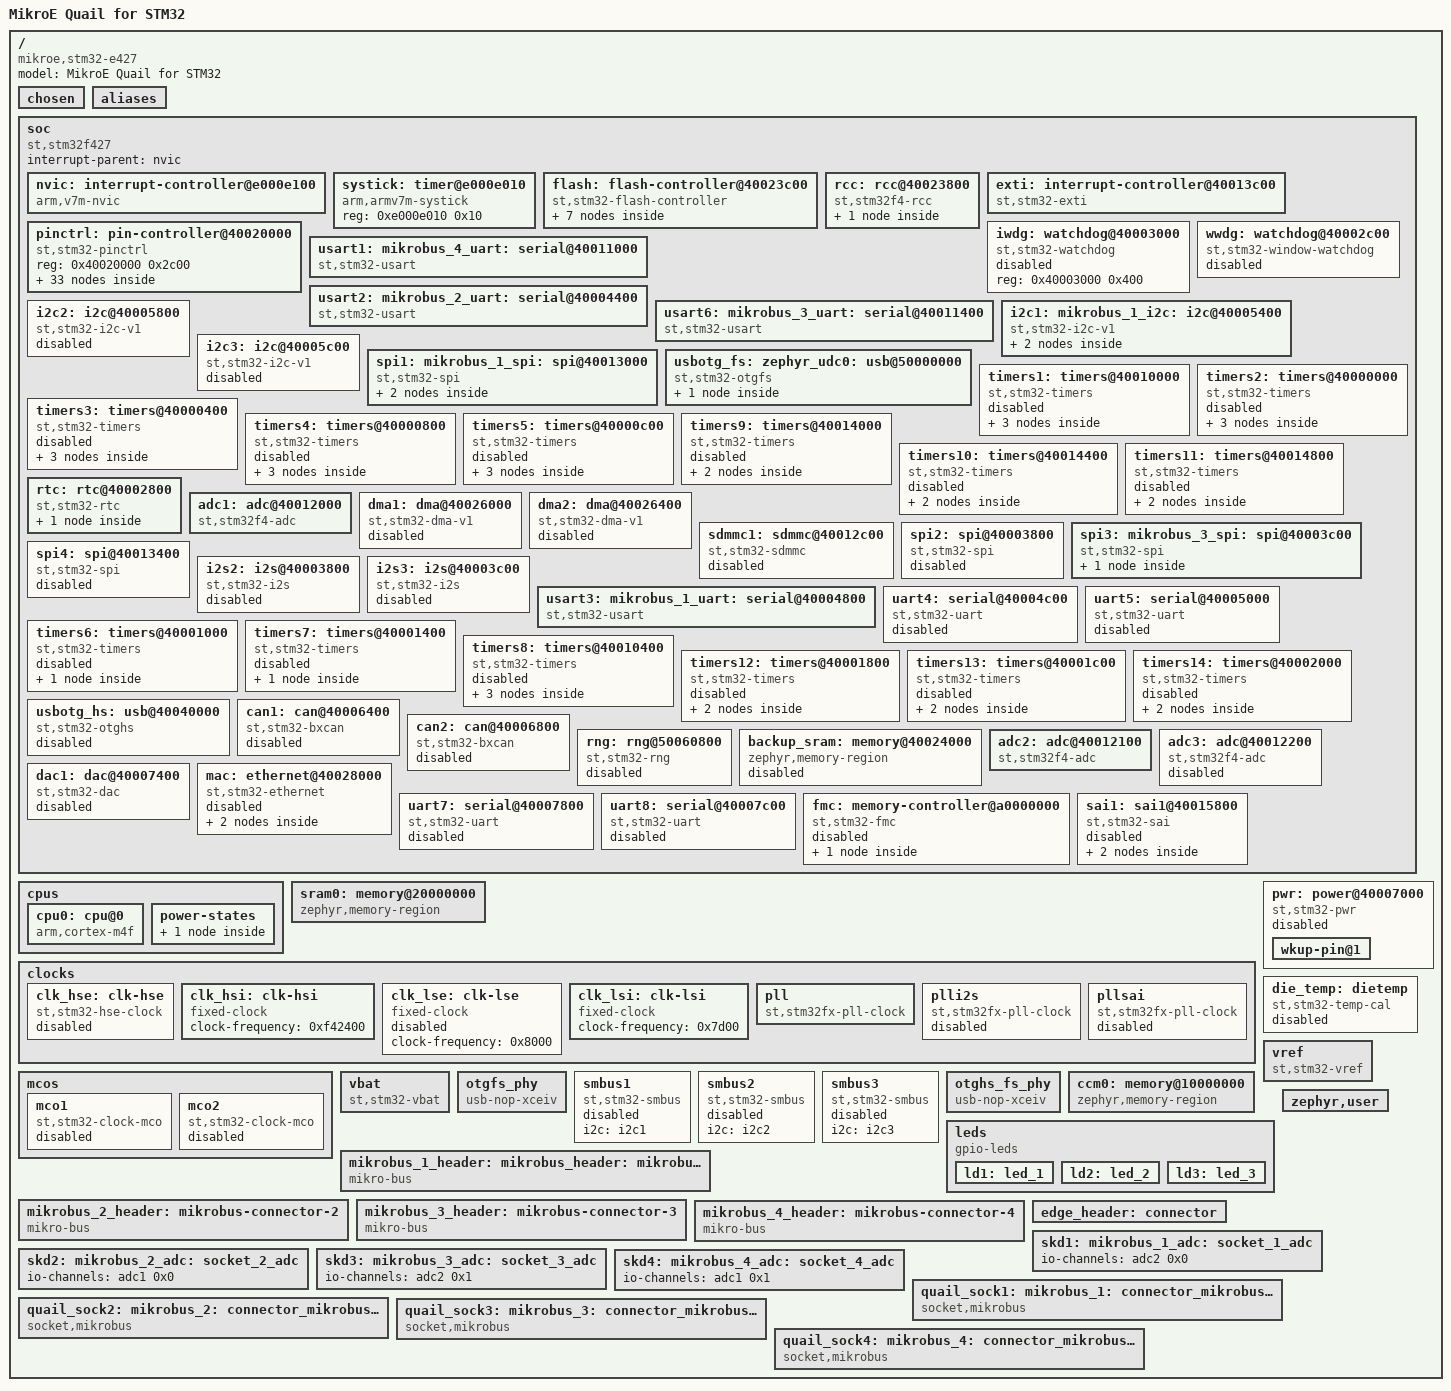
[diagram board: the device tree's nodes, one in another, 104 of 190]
/dts-v1/;

/* node '/' defined in zephyr/dts/common/skeleton.dtsi:9 */
/ {
	#address-cells = < 0x1 >;         /* in zephyr/dts/common/skeleton.dtsi:10 */
	#size-cells = < 0x1 >;            /* in zephyr/dts/common/skeleton.dtsi:11 */
	model = "MikroE Quail for STM32"; /* in zephyr/boards/mikroe/quail/mikroe_quail.dts:13 */
	compatible = "mikroe,stm32-e427",
	             "st,stm32f427";      /* in zephyr/boards/mikroe/quail/mikroe_quail.dts:14 */

	/* node '/chosen' defined in zephyr/dts/common/skeleton.dtsi:13 */
	chosen {
		zephyr,system-timer-companion = &rtc;     /* in zephyr/dts/arm/st/f4/stm32f4.dtsi:27 */
		zephyr,entropy = &rng;                    /* in zephyr/dts/arm/st/f4/stm32f405.dtsi:13 */
		zephyr,sram = &sram0;                     /* in zephyr/boards/mikroe/quail/mikroe_quail.dts:17 */
		zephyr,flash = &flash0;                   /* in zephyr/boards/mikroe/quail/mikroe_quail.dts:18 */
		zephyr,flash-controller = &flash1;        /* in zephyr/boards/mikroe/quail/mikroe_quail.dts:19 */
		zephyr,dtcm = &ccm0;                      /* in zephyr/boards/mikroe/quail/mikroe_quail.dts:20 */
		zephyr,console = &board_cdc_acm_uart;     /* in zephyr/boards/common/usb/cdc_acm_serial.dtsi:9 */
		zephyr,shell-uart = &board_cdc_acm_uart;  /* in zephyr/boards/common/usb/cdc_acm_serial.dtsi:10 */
		zephyr,uart-mcumgr = &board_cdc_acm_uart; /* in zephyr/boards/common/usb/cdc_acm_serial.dtsi:11 */
		zephyr,bt-mon-uart = &board_cdc_acm_uart; /* in zephyr/boards/common/usb/cdc_acm_serial.dtsi:12 */
		zephyr,bt-c2h-uart = &board_cdc_acm_uart; /* in zephyr/boards/common/usb/cdc_acm_serial.dtsi:13 */
	};

	/* node '/aliases' defined in zephyr/dts/common/skeleton.dtsi:15 */
	aliases {
		led0 = &ld1;          /* in zephyr/boards/mikroe/quail/mikroe_quail.dts:174 */
		led1 = &ld2;          /* in zephyr/boards/mikroe/quail/mikroe_quail.dts:175 */
		led2 = &ld3;          /* in zephyr/boards/mikroe/quail/mikroe_quail.dts:176 */
		volt-sensor0 = &vref; /* in zephyr/boards/mikroe/quail/mikroe_quail.dts:177 */
		volt-sensor1 = &vbat; /* in zephyr/boards/mikroe/quail/mikroe_quail.dts:178 */
	};

	/* node '/soc' defined in zephyr/dts/arm/armv7-m.dtsi:6 */
	soc {
		#address-cells = < 0x1 >;     /* in zephyr/dts/arm/armv7-m.dtsi:7 */
		#size-cells = < 0x1 >;        /* in zephyr/dts/arm/armv7-m.dtsi:8 */
		interrupt-parent = < &nvic >; /* in zephyr/dts/arm/armv7-m.dtsi:10 */
		ranges;                       /* in zephyr/dts/arm/armv7-m.dtsi:11 */
		compatible = "st,stm32f427",
		             "st,stm32f4",
		             "simple-bus";    /* in zephyr/dts/arm/st/f4/stm32f427.dtsi:22 */

		/* node '/soc/interrupt-controller@e000e100' defined in zephyr/dts/arm/armv7-m.dtsi:13 */
		nvic: interrupt-controller@e000e100 {
			#address-cells = < 0x1 >;            /* in zephyr/dts/arm/armv7-m.dtsi:14 */
			compatible = "arm,v7m-nvic";         /* in zephyr/dts/arm/armv7-m.dtsi:15 */
			reg = < 0xe000e100 0xc00 >;          /* in zephyr/dts/arm/armv7-m.dtsi:16 */
			interrupt-controller;                /* in zephyr/dts/arm/armv7-m.dtsi:17 */
			#interrupt-cells = < 0x2 >;          /* in zephyr/dts/arm/armv7-m.dtsi:18 */
			arm,num-irq-priority-bits = < 0x4 >; /* in zephyr/dts/arm/st/f4/stm32f4.dtsi:730 */
			phandle = < 0x1 >;                   /* in zephyr/dts/arm/armv7-m.dtsi:10 */
		};

		/* node '/soc/timer@e000e010' defined in zephyr/dts/arm/armv7-m.dtsi:21 */
		systick: timer@e000e010 {
			compatible = "arm,armv7m-systick"; /* in zephyr/dts/arm/armv7-m.dtsi:22 */
			reg = < 0xe000e010 0x10 >;         /* in zephyr/dts/arm/armv7-m.dtsi:23 */
		};

		/* node '/soc/flash-controller@40023c00' defined in zephyr/dts/arm/st/f4/stm32f4.dtsi:112 */
		flash: flash-controller@40023c00 {
			compatible = "st,stm32-flash-controller",
			             "st,stm32f4-flash-controller"; /* in zephyr/dts/arm/st/f4/stm32f4.dtsi:113 */
			reg = < 0x40023c00 0x400 >;                 /* in zephyr/dts/arm/st/f4/stm32f4.dtsi:114 */
			interrupts = < 0x4 0x0 >;                   /* in zephyr/dts/arm/st/f4/stm32f4.dtsi:115 */
			#address-cells = < 0x1 >;                   /* in zephyr/dts/arm/st/f4/stm32f4.dtsi:117 */
			#size-cells = < 0x1 >;                      /* in zephyr/dts/arm/st/f4/stm32f4.dtsi:118 */
			ranges;                                     /* in zephyr/dts/arm/st/f4/stm32f4.dtsi:119 */

			/* node '/soc/flash-controller@40023c00/flash@8000000' defined in zephyr/dts/arm/st/f4/stm32f4.dtsi:121 */
			flash0: flash@8000000 {
				compatible = "st,stm32f4-nv-flash",
				             "st,stm32-nv-flash",
				             "soc-nv-flash";         /* in zephyr/dts/arm/st/f4/stm32f4.dtsi:122 */
				#address-cells = < 0x1 >;            /* in zephyr/dts/arm/st/f4/stm32f4.dtsi:124 */
				#size-cells = < 0x1 >;               /* in zephyr/dts/arm/st/f4/stm32f4.dtsi:125 */
				write-block-size = < 0x1 >;          /* in zephyr/dts/arm/st/f4/stm32f4.dtsi:126 */
				max-erase-time = < 0xfa0 >;          /* in zephyr/dts/arm/st/f4/stm32f4.dtsi:128 */
				reg = < 0x8000000 0x200000 >;        /* in zephyr/dts/arm/st/f4/stm32f427vi.dtsi:23 */
				ranges = < 0x0 0x8000000 0x200000 >; /* in zephyr/dts/arm/st/f4/stm32f427vi.dtsi:24 */
			};

			/* node '/soc/flash-controller@40023c00/flash@1fff7800' defined in zephyr/dts/arm/st/f4/stm32f4.dtsi:131 */
			st_nvm_user_otp: flash@1fff7800 {
				compatible = "st,stm32-nvm-otp"; /* in zephyr/dts/arm/st/f4/stm32f4.dtsi:132 */
				reg = < 0x1fff7800 0x200 >;      /* in zephyr/dts/arm/st/f4/stm32f4.dtsi:133 */
				status = "disabled";             /* in zephyr/dts/arm/st/f4/stm32f4.dtsi:134 */
			};

			/* node '/soc/flash-controller@40023c00/flash@1fff7a00' defined in zephyr/dts/arm/st/f4/stm32f4.dtsi:148 */
			flash@1fff7a00 {
				compatible = "st,stm32-nvm-otp"; /* in zephyr/dts/arm/st/f4/stm32f4.dtsi:149 */
				reg = < 0x1fff7a00 0x100 >;      /* in zephyr/dts/arm/st/f4/stm32f4.dtsi:150 */

				/* node '/soc/flash-controller@40023c00/flash@1fff7a00/nvmem-layout' defined in zephyr/dts/arm/st/f4/stm32f4.dtsi:152 */
				nvmem-layout {
					compatible = "fixed-layout"; /* in zephyr/dts/arm/st/f4/stm32f4.dtsi:153 */
					#address-cells = < 0x1 >;    /* in zephyr/dts/arm/st/f4/stm32f4.dtsi:154 */
					#size-cells = < 0x1 >;       /* in zephyr/dts/arm/st/f4/stm32f4.dtsi:155 */

					/* node '/soc/flash-controller@40023c00/flash@1fff7a00/nvmem-layout/vrefint@2a' defined in zephyr/dts/arm/st/f4/stm32f4.dtsi:157 */
					vrefint_otp: vrefint@2a {
						reg = < 0x2a 0x2 >;          /* in zephyr/dts/arm/st/f4/stm32f4.dtsi:158 */
						#nvmem-cell-cells = < 0x0 >; /* in zephyr/dts/arm/st/f4/stm32f4.dtsi:159 */
						read-only;                   /* in zephyr/dts/arm/st/f4/stm32f4.dtsi:160 */
						phandle = < 0x2b >;          /* in zephyr/dts/arm/st/f4/stm32f4.dtsi:686 */
					};

					/* node '/soc/flash-controller@40023c00/flash@1fff7a00/nvmem-layout/ts-cal1@2c' defined in zephyr/dts/arm/st/f4/stm32f4.dtsi:163 */
					ts_cal1_otp: ts-cal1@2c {
						reg = < 0x2c 0x2 >;          /* in zephyr/dts/arm/st/f4/stm32f4.dtsi:164 */
						#nvmem-cell-cells = < 0x0 >; /* in zephyr/dts/arm/st/f4/stm32f4.dtsi:165 */
						read-only;                   /* in zephyr/dts/arm/st/f4/stm32f4.dtsi:166 */
						phandle = < 0x28 >;          /* in zephyr/dts/arm/st/f4/stm32f4.dtsi:675 */
					};

					/* node '/soc/flash-controller@40023c00/flash@1fff7a00/nvmem-layout/ts-cal2@2e' defined in zephyr/dts/arm/st/f4/stm32f4.dtsi:169 */
					ts_cal2_otp: ts-cal2@2e {
						reg = < 0x2e 0x2 >;          /* in zephyr/dts/arm/st/f4/stm32f4.dtsi:170 */
						#nvmem-cell-cells = < 0x0 >; /* in zephyr/dts/arm/st/f4/stm32f4.dtsi:171 */
						read-only;                   /* in zephyr/dts/arm/st/f4/stm32f4.dtsi:172 */
						phandle = < 0x29 >;          /* in zephyr/dts/arm/st/f4/stm32f4.dtsi:675 */
					};
				};
			};
		};

		/* node '/soc/rcc@40023800' defined in zephyr/dts/arm/st/f4/stm32f4.dtsi:178 */
		rcc: rcc@40023800 {
			#clock-cells = < 0x2 >;          /* in zephyr/dts/arm/st/f4/stm32f4.dtsi:180 */
			reg = < 0x40023800 0x400 >;      /* in zephyr/dts/arm/st/f4/stm32f4.dtsi:181 */
			compatible = "st,stm32f4-rcc";   /* in zephyr/dts/arm/st/f4/stm32f427.dtsi:25 */
			clocks = < &pll >;               /* in zephyr/boards/mikroe/quail/mikroe_quail.dts:221 */
			clock-frequency = < 0x5b8d800 >; /* in zephyr/boards/mikroe/quail/mikroe_quail.dts:222 */
			ahb-prescaler = < 0x1 >;         /* in zephyr/boards/mikroe/quail/mikroe_quail.dts:223 */
			apb1-prescaler = < 0x4 >;        /* in zephyr/boards/mikroe/quail/mikroe_quail.dts:224 */
			apb2-prescaler = < 0x2 >;        /* in zephyr/boards/mikroe/quail/mikroe_quail.dts:225 */
			phandle = < 0x3 >;               /* in zephyr/dts/arm/st/f4/stm32f4.dtsi:195 */

			/* node '/soc/rcc@40023800/reset-controller' defined in zephyr/dts/arm/st/f4/stm32f4.dtsi:183 */
			rctl: reset-controller {
				compatible = "st,stm32-rcc-rctl"; /* in zephyr/dts/arm/st/f4/stm32f4.dtsi:184 */
				#reset-cells = < 0x1 >;           /* in zephyr/dts/arm/st/f4/stm32f4.dtsi:185 */
				phandle = < 0x4 >;                /* in zephyr/dts/arm/st/f4/stm32f4.dtsi:295 */
			};
		};

		/* node '/soc/interrupt-controller@40013c00' defined in zephyr/dts/arm/st/f4/stm32f4.dtsi:189 */
		exti: interrupt-controller@40013c00 {
			compatible = "st,stm32-exti";  /* in zephyr/dts/arm/st/f4/stm32f4.dtsi:190 */
			interrupt-controller;          /* in zephyr/dts/arm/st/f4/stm32f4.dtsi:191 */
			#interrupt-cells = < 0x1 >;    /* in zephyr/dts/arm/st/f4/stm32f4.dtsi:192 */
			#address-cells = < 0x0 >;      /* in zephyr/dts/arm/st/f4/stm32f4.dtsi:193 */
			reg = < 0x40013c00 0x400 >;    /* in zephyr/dts/arm/st/f4/stm32f4.dtsi:194 */
			clocks = < &rcc 0x44 0x4000 >; /* in zephyr/dts/arm/st/f4/stm32f4.dtsi:195 */
			num-lines = < 0x20 >;          /* in zephyr/dts/arm/st/f4/stm32f4.dtsi:196 */
			interrupts = < 0x6 0x0 >,
			             < 0x7 0x0 >,
			             < 0x8 0x0 >,
			             < 0x9 0x0 >,
			             < 0xa 0x0 >,
			             < 0x17 0x0 >,
			             < 0x28 0x0 >;     /* in zephyr/dts/arm/st/f4/stm32f4.dtsi:197 */
			interrupt-names = "line0",
			                  "line1",
			                  "line2",
			                  "line3",
			                  "line4",
			                  "line5-9",
			                  "line10-15"; /* in zephyr/dts/arm/st/f4/stm32f4.dtsi:199 */
			line-ranges = < 0x0 0x1 >,
			              < 0x1 0x1 >,
			              < 0x2 0x1 >,
			              < 0x3 0x1 >,
			              < 0x4 0x1 >,
			              < 0x5 0x5 >,
			              < 0xa 0x6 >;     /* in zephyr/dts/arm/st/f4/stm32f4.dtsi:201 */
		};

		/* node '/soc/pin-controller@40020000' defined in zephyr/dts/arm/st/f4/stm32f4.dtsi:205 */
		pinctrl: pin-controller@40020000 {
			compatible = "st,stm32-pinctrl"; /* in zephyr/dts/arm/st/f4/stm32f4.dtsi:206 */
			#address-cells = < 0x1 >;        /* in zephyr/dts/arm/st/f4/stm32f4.dtsi:207 */
			#size-cells = < 0x1 >;           /* in zephyr/dts/arm/st/f4/stm32f4.dtsi:208 */
			ranges;                          /* in zephyr/dts/arm/st/f4/stm32f4.dtsi:210 */
			reg = < 0x40020000 0x2c00 >;     /* in zephyr/dts/arm/st/f4/stm32f427.dtsi:29 */

			/* node '/soc/pin-controller@40020000/gpio@40020000' defined in zephyr/dts/arm/st/f4/stm32f4.dtsi:212 */
			gpioa: gpio@40020000 {
				compatible = "st,stm32-gpio"; /* in zephyr/dts/arm/st/f4/stm32f4.dtsi:213 */
				gpio-controller;              /* in zephyr/dts/arm/st/f4/stm32f4.dtsi:214 */
				#gpio-cells = < 0x2 >;        /* in zephyr/dts/arm/st/f4/stm32f4.dtsi:215 */
				reg = < 0x40020000 0x400 >;   /* in zephyr/dts/arm/st/f4/stm32f4.dtsi:216 */
				clocks = < &rcc 0x30 0x1 >;   /* in zephyr/dts/arm/st/f4/stm32f4.dtsi:217 */
				phandle = < 0x1e >;           /* in zephyr/boards/mikroe/quail/mikroe_quail.dts:282 */
			};

			/* node '/soc/pin-controller@40020000/gpio@40020400' defined in zephyr/dts/arm/st/f4/stm32f4.dtsi:220 */
			gpiob: gpio@40020400 {
				compatible = "st,stm32-gpio"; /* in zephyr/dts/arm/st/f4/stm32f4.dtsi:221 */
				gpio-controller;              /* in zephyr/dts/arm/st/f4/stm32f4.dtsi:222 */
				#gpio-cells = < 0x2 >;        /* in zephyr/dts/arm/st/f4/stm32f4.dtsi:223 */
				reg = < 0x40020400 0x400 >;   /* in zephyr/dts/arm/st/f4/stm32f4.dtsi:224 */
				clocks = < &rcc 0x30 0x2 >;   /* in zephyr/dts/arm/st/f4/stm32f4.dtsi:225 */
				phandle = < 0xd >;            /* in zephyr/boards/mikroe/quail/mikroe_quail.dts:306 */
			};

			/* node '/soc/pin-controller@40020000/gpio@40020800' defined in zephyr/dts/arm/st/f4/stm32f4.dtsi:228 */
			gpioc: gpio@40020800 {
				compatible = "st,stm32-gpio"; /* in zephyr/dts/arm/st/f4/stm32f4.dtsi:229 */
				gpio-controller;              /* in zephyr/dts/arm/st/f4/stm32f4.dtsi:230 */
				#gpio-cells = < 0x2 >;        /* in zephyr/dts/arm/st/f4/stm32f4.dtsi:231 */
				reg = < 0x40020800 0x400 >;   /* in zephyr/dts/arm/st/f4/stm32f4.dtsi:232 */
				clocks = < &rcc 0x30 0x4 >;   /* in zephyr/dts/arm/st/f4/stm32f4.dtsi:233 */
				phandle = < 0x30 >;           /* in zephyr/boards/mikroe/quail/mikroe_quail.dts:37 */
			};

			/* node '/soc/pin-controller@40020000/gpio@40020c00' defined in zephyr/dts/arm/st/f4/stm32f4.dtsi:236 */
			gpiod: gpio@40020c00 {
				compatible = "st,stm32-gpio"; /* in zephyr/dts/arm/st/f4/stm32f4.dtsi:237 */
				gpio-controller;              /* in zephyr/dts/arm/st/f4/stm32f4.dtsi:238 */
				#gpio-cells = < 0x2 >;        /* in zephyr/dts/arm/st/f4/stm32f4.dtsi:239 */
				reg = < 0x40020c00 0x400 >;   /* in zephyr/dts/arm/st/f4/stm32f4.dtsi:240 */
				clocks = < &rcc 0x30 0x8 >;   /* in zephyr/dts/arm/st/f4/stm32f4.dtsi:241 */
				phandle = < 0x1d >;           /* in zephyr/boards/mikroe/quail/mikroe_quail.dts:282 */
			};

			/* node '/soc/pin-controller@40020000/gpio@40021000' defined in zephyr/dts/arm/st/f4/stm32f4.dtsi:244 */
			gpioe: gpio@40021000 {
				compatible = "st,stm32-gpio"; /* in zephyr/dts/arm/st/f4/stm32f4.dtsi:245 */
				gpio-controller;              /* in zephyr/dts/arm/st/f4/stm32f4.dtsi:246 */
				#gpio-cells = < 0x2 >;        /* in zephyr/dts/arm/st/f4/stm32f4.dtsi:247 */
				reg = < 0x40021000 0x400 >;   /* in zephyr/dts/arm/st/f4/stm32f4.dtsi:248 */
				clocks = < &rcc 0x30 0x10 >;  /* in zephyr/dts/arm/st/f4/stm32f4.dtsi:249 */
				phandle = < 0x2f >;           /* in zephyr/boards/mikroe/quail/mikroe_quail.dts:27 */
			};

			/* node '/soc/pin-controller@40020000/gpio@40021400' defined in zephyr/dts/arm/st/f4/stm32f4.dtsi:252 */
			gpiof: gpio@40021400 {
				compatible = "st,stm32-gpio"; /* in zephyr/dts/arm/st/f4/stm32f405.dtsi:27 */
				gpio-controller;              /* in zephyr/dts/arm/st/f4/stm32f405.dtsi:28 */
				#gpio-cells = < 0x2 >;        /* in zephyr/dts/arm/st/f4/stm32f405.dtsi:29 */
				reg = < 0x40021400 0x400 >;   /* in zephyr/dts/arm/st/f4/stm32f405.dtsi:30 */
				clocks = < &rcc 0x30 0x20 >;  /* in zephyr/dts/arm/st/f4/stm32f405.dtsi:31 */
			};

			/* node '/soc/pin-controller@40020000/gpio@40021800' defined in zephyr/dts/arm/st/f4/stm32f4.dtsi:260 */
			gpiog: gpio@40021800 {
				compatible = "st,stm32-gpio"; /* in zephyr/dts/arm/st/f4/stm32f405.dtsi:35 */
				gpio-controller;              /* in zephyr/dts/arm/st/f4/stm32f405.dtsi:36 */
				#gpio-cells = < 0x2 >;        /* in zephyr/dts/arm/st/f4/stm32f405.dtsi:37 */
				reg = < 0x40021800 0x400 >;   /* in zephyr/dts/arm/st/f4/stm32f405.dtsi:38 */
				clocks = < &rcc 0x30 0x40 >;  /* in zephyr/dts/arm/st/f4/stm32f405.dtsi:39 */
			};

			/* node '/soc/pin-controller@40020000/gpio@40021c00' defined in zephyr/dts/arm/st/f4/stm32f4.dtsi:268 */
			gpioh: gpio@40021c00 {
				compatible = "st,stm32-gpio"; /* in zephyr/dts/arm/st/f4/stm32f4.dtsi:269 */
				gpio-controller;              /* in zephyr/dts/arm/st/f4/stm32f4.dtsi:270 */
				#gpio-cells = < 0x2 >;        /* in zephyr/dts/arm/st/f4/stm32f4.dtsi:271 */
				reg = < 0x40021c00 0x400 >;   /* in zephyr/dts/arm/st/f4/stm32f4.dtsi:272 */
				clocks = < &rcc 0x30 0x80 >;  /* in zephyr/dts/arm/st/f4/stm32f4.dtsi:273 */
			};

			/* node '/soc/pin-controller@40020000/gpio@40022000' defined in zephyr/dts/arm/st/f4/stm32f405.dtsi:42 */
			gpioi: gpio@40022000 {
				compatible = "st,stm32-gpio"; /* in zephyr/dts/arm/st/f4/stm32f405.dtsi:43 */
				gpio-controller;              /* in zephyr/dts/arm/st/f4/stm32f405.dtsi:44 */
				#gpio-cells = < 0x2 >;        /* in zephyr/dts/arm/st/f4/stm32f405.dtsi:45 */
				reg = < 0x40022000 0x400 >;   /* in zephyr/dts/arm/st/f4/stm32f405.dtsi:46 */
				clocks = < &rcc 0x30 0x100 >; /* in zephyr/dts/arm/st/f4/stm32f405.dtsi:47 */
			};

			/* node '/soc/pin-controller@40020000/gpio@40022400' defined in zephyr/dts/arm/st/f4/stm32f427.dtsi:31 */
			gpioj: gpio@40022400 {
				compatible = "st,stm32-gpio"; /* in zephyr/dts/arm/st/f4/stm32f427.dtsi:32 */
				gpio-controller;              /* in zephyr/dts/arm/st/f4/stm32f427.dtsi:33 */
				#gpio-cells = < 0x2 >;        /* in zephyr/dts/arm/st/f4/stm32f427.dtsi:34 */
				reg = < 0x40022400 0x400 >;   /* in zephyr/dts/arm/st/f4/stm32f427.dtsi:35 */
				clocks = < &rcc 0x30 0x200 >; /* in zephyr/dts/arm/st/f4/stm32f427.dtsi:36 */
			};

			/* node '/soc/pin-controller@40020000/gpio@40022800' defined in zephyr/dts/arm/st/f4/stm32f427.dtsi:39 */
			gpiok: gpio@40022800 {
				compatible = "st,stm32-gpio"; /* in zephyr/dts/arm/st/f4/stm32f427.dtsi:40 */
				gpio-controller;              /* in zephyr/dts/arm/st/f4/stm32f427.dtsi:41 */
				#gpio-cells = < 0x2 >;        /* in zephyr/dts/arm/st/f4/stm32f427.dtsi:42 */
				reg = < 0x40022800 0x400 >;   /* in zephyr/dts/arm/st/f4/stm32f427.dtsi:43 */
				clocks = < &rcc 0x30 0x400 >; /* in zephyr/dts/arm/st/f4/stm32f427.dtsi:44 */
			};

			/* node '/soc/pin-controller@40020000/adc1_in4_pa4' defined in modules/hal/stm32/dts/st/f4/stm32f427v(g-i)tx-pinctrl.dtsi:29 */
			adc1_in4_pa4: adc1_in4_pa4 {
				pinmux = < 0x90 >;  /* in modules/hal/stm32/dts/st/f4/stm32f427v(g-i)tx-pinctrl.dtsi:30 */
				phandle = < 0x18 >; /* in zephyr/boards/mikroe/quail/mikroe_quail.dts:313 */
			};

			/* node '/soc/pin-controller@40020000/adc1_in5_pa5' defined in modules/hal/stm32/dts/st/f4/stm32f427v(g-i)tx-pinctrl.dtsi:33 */
			adc1_in5_pa5: adc1_in5_pa5 {
				pinmux = < 0xb0 >;  /* in modules/hal/stm32/dts/st/f4/stm32f427v(g-i)tx-pinctrl.dtsi:34 */
				phandle = < 0x19 >; /* in zephyr/boards/mikroe/quail/mikroe_quail.dts:313 */
			};

			/* node '/soc/pin-controller@40020000/adc2_in6_pa6' defined in modules/hal/stm32/dts/st/f4/stm32f427v(g-i)tx-pinctrl.dtsi:101 */
			adc2_in6_pa6: adc2_in6_pa6 {
				pinmux = < 0xd0 >;  /* in modules/hal/stm32/dts/st/f4/stm32f427v(g-i)tx-pinctrl.dtsi:102 */
				phandle = < 0x23 >; /* in zephyr/boards/mikroe/quail/mikroe_quail.dts:321 */
			};

			/* node '/soc/pin-controller@40020000/adc2_in7_pa7' defined in modules/hal/stm32/dts/st/f4/stm32f427v(g-i)tx-pinctrl.dtsi:105 */
			adc2_in7_pa7: adc2_in7_pa7 {
				pinmux = < 0xf0 >;  /* in modules/hal/stm32/dts/st/f4/stm32f427v(g-i)tx-pinctrl.dtsi:106 */
				phandle = < 0x24 >; /* in zephyr/boards/mikroe/quail/mikroe_quail.dts:321 */
			};

			/* node '/soc/pin-controller@40020000/i2c1_scl_pb6' defined in modules/hal/stm32/dts/st/f4/stm32f427v(g-i)tx-pinctrl.dtsi:1029 */
			i2c1_scl_pb6: i2c1_scl_pb6 {
				pinmux = < 0x2c4 >; /* in modules/hal/stm32/dts/st/f4/stm32f427v(g-i)tx-pinctrl.dtsi:1030 */
				bias-pull-up;       /* in modules/hal/stm32/dts/st/f4/stm32f427v(g-i)tx-pinctrl.dtsi:1031 */
				drive-open-drain;   /* in modules/hal/stm32/dts/st/f4/stm32f427v(g-i)tx-pinctrl.dtsi:1032 */
				phandle = < 0xb >;  /* in zephyr/boards/mikroe/quail/mikroe_quail.dts:304 */
			};

			/* node '/soc/pin-controller@40020000/i2c1_sda_pb7' defined in modules/hal/stm32/dts/st/f4/stm32f427v(g-i)tx-pinctrl.dtsi:1055 */
			i2c1_sda_pb7: i2c1_sda_pb7 {
				pinmux = < 0x2e4 >; /* in modules/hal/stm32/dts/st/f4/stm32f427v(g-i)tx-pinctrl.dtsi:1056 */
				bias-pull-up;       /* in modules/hal/stm32/dts/st/f4/stm32f427v(g-i)tx-pinctrl.dtsi:1057 */
				drive-open-drain;   /* in modules/hal/stm32/dts/st/f4/stm32f427v(g-i)tx-pinctrl.dtsi:1058 */
				phandle = < 0xc >;  /* in zephyr/boards/mikroe/quail/mikroe_quail.dts:304 */
			};

			/* node '/soc/pin-controller@40020000/spi1_miso_pb4' defined in modules/hal/stm32/dts/st/f4/stm32f427v(g-i)tx-pinctrl.dtsi:1325 */
			spi1_miso_pb4: spi1_miso_pb4 {
				pinmux = < 0x285 >;            /* in modules/hal/stm32/dts/st/f4/stm32f427v(g-i)tx-pinctrl.dtsi:1326 */
				bias-pull-down;                /* in modules/hal/stm32/dts/st/f4/stm32f427v(g-i)tx-pinctrl.dtsi:1327 */
				slew-rate = "very-high-speed"; /* in modules/hal/stm32/dts/st/f4/stm32f427v(g-i)tx-pinctrl.dtsi:1328 */
				phandle = < 0x11 >;            /* in zephyr/boards/mikroe/quail/mikroe_quail.dts:271 */
			};

			/* node '/soc/pin-controller@40020000/spi3_miso_pc11' defined in modules/hal/stm32/dts/st/f4/stm32f427v(g-i)tx-pinctrl.dtsi:1349 */
			spi3_miso_pc11: spi3_miso_pc11 {
				pinmux = < 0x566 >;            /* in modules/hal/stm32/dts/st/f4/stm32f427v(g-i)tx-pinctrl.dtsi:1350 */
				bias-pull-down;                /* in modules/hal/stm32/dts/st/f4/stm32f427v(g-i)tx-pinctrl.dtsi:1351 */
				slew-rate = "very-high-speed"; /* in modules/hal/stm32/dts/st/f4/stm32f427v(g-i)tx-pinctrl.dtsi:1352 */
				phandle = < 0x1b >;            /* in zephyr/boards/mikroe/quail/mikroe_quail.dts:279 */
			};

			/* node '/soc/pin-controller@40020000/spi1_mosi_pb5' defined in modules/hal/stm32/dts/st/f4/stm32f427v(g-i)tx-pinctrl.dtsi:1375 */
			spi1_mosi_pb5: spi1_mosi_pb5 {
				pinmux = < 0x2a5 >;            /* in modules/hal/stm32/dts/st/f4/stm32f427v(g-i)tx-pinctrl.dtsi:1376 */
				bias-pull-down;                /* in modules/hal/stm32/dts/st/f4/stm32f427v(g-i)tx-pinctrl.dtsi:1377 */
				slew-rate = "very-high-speed"; /* in modules/hal/stm32/dts/st/f4/stm32f427v(g-i)tx-pinctrl.dtsi:1378 */
				phandle = < 0x12 >;            /* in zephyr/boards/mikroe/quail/mikroe_quail.dts:271 */
			};

			/* node '/soc/pin-controller@40020000/spi3_mosi_pc12' defined in modules/hal/stm32/dts/st/f4/stm32f427v(g-i)tx-pinctrl.dtsi:1399 */
			spi3_mosi_pc12: spi3_mosi_pc12 {
				pinmux = < 0x586 >;            /* in modules/hal/stm32/dts/st/f4/stm32f427v(g-i)tx-pinctrl.dtsi:1400 */
				bias-pull-down;                /* in modules/hal/stm32/dts/st/f4/stm32f427v(g-i)tx-pinctrl.dtsi:1401 */
				slew-rate = "very-high-speed"; /* in modules/hal/stm32/dts/st/f4/stm32f427v(g-i)tx-pinctrl.dtsi:1402 */
				phandle = < 0x1c >;            /* in zephyr/boards/mikroe/quail/mikroe_quail.dts:279 */
			};

			/* node '/soc/pin-controller@40020000/spi1_sck_pb3' defined in modules/hal/stm32/dts/st/f4/stm32f427v(g-i)tx-pinctrl.dtsi:1481 */
			spi1_sck_pb3: spi1_sck_pb3 {
				pinmux = < 0x265 >;            /* in modules/hal/stm32/dts/st/f4/stm32f427v(g-i)tx-pinctrl.dtsi:1482 */
				bias-pull-down;                /* in modules/hal/stm32/dts/st/f4/stm32f427v(g-i)tx-pinctrl.dtsi:1483 */
				slew-rate = "very-high-speed"; /* in modules/hal/stm32/dts/st/f4/stm32f427v(g-i)tx-pinctrl.dtsi:1484 */
				phandle = < 0x10 >;            /* in zephyr/boards/mikroe/quail/mikroe_quail.dts:271 */
			};

			/* node '/soc/pin-controller@40020000/spi3_sck_pc10' defined in modules/hal/stm32/dts/st/f4/stm32f427v(g-i)tx-pinctrl.dtsi:1511 */
			spi3_sck_pc10: spi3_sck_pc10 {
				pinmux = < 0x546 >;            /* in modules/hal/stm32/dts/st/f4/stm32f427v(g-i)tx-pinctrl.dtsi:1512 */
				bias-pull-down;                /* in modules/hal/stm32/dts/st/f4/stm32f427v(g-i)tx-pinctrl.dtsi:1513 */
				slew-rate = "very-high-speed"; /* in modules/hal/stm32/dts/st/f4/stm32f427v(g-i)tx-pinctrl.dtsi:1514 */
				phandle = < 0x1a >;            /* in zephyr/boards/mikroe/quail/mikroe_quail.dts:279 */
			};

			/* node '/soc/pin-controller@40020000/usart1_rx_pa10' defined in modules/hal/stm32/dts/st/f4/stm32f427v(g-i)tx-pinctrl.dtsi:1877 */
			usart1_rx_pa10: usart1_rx_pa10 {
				pinmux = < 0x147 >; /* in modules/hal/stm32/dts/st/f4/stm32f427v(g-i)tx-pinctrl.dtsi:1878 */
				phandle = < 0x6 >;  /* in zephyr/boards/mikroe/quail/mikroe_quail.dts:229 */
			};

			/* node '/soc/pin-controller@40020000/usart2_rx_pd6' defined in modules/hal/stm32/dts/st/f4/stm32f427v(g-i)tx-pinctrl.dtsi:1889 */
			usart2_rx_pd6: usart2_rx_pd6 {
				pinmux = < 0x6c7 >; /* in modules/hal/stm32/dts/st/f4/stm32f427v(g-i)tx-pinctrl.dtsi:1890 */
				phandle = < 0x8 >;  /* in zephyr/boards/mikroe/quail/mikroe_quail.dts:236 */
			};

			/* node '/soc/pin-controller@40020000/usart3_rx_pd9' defined in modules/hal/stm32/dts/st/f4/stm32f427v(g-i)tx-pinctrl.dtsi:1901 */
			usart3_rx_pd9: usart3_rx_pd9 {
				pinmux = < 0x727 >; /* in modules/hal/stm32/dts/st/f4/stm32f427v(g-i)tx-pinctrl.dtsi:1902 */
				phandle = < 0x21 >; /* in zephyr/boards/mikroe/quail/mikroe_quail.dts:243 */
			};

			/* node '/soc/pin-controller@40020000/usart6_rx_pc7' defined in modules/hal/stm32/dts/st/f4/stm32f427v(g-i)tx-pinctrl.dtsi:1917 */
			usart6_rx_pc7: usart6_rx_pc7 {
				pinmux = < 0x4e8 >; /* in modules/hal/stm32/dts/st/f4/stm32f427v(g-i)tx-pinctrl.dtsi:1918 */
				phandle = < 0xa >;  /* in zephyr/boards/mikroe/quail/mikroe_quail.dts:250 */
			};

			/* node '/soc/pin-controller@40020000/usart1_tx_pa9' defined in modules/hal/stm32/dts/st/f4/stm32f427v(g-i)tx-pinctrl.dtsi:1931 */
			usart1_tx_pa9: usart1_tx_pa9 {
				pinmux = < 0x127 >; /* in modules/hal/stm32/dts/st/f4/stm32f427v(g-i)tx-pinctrl.dtsi:1932 */
				bias-pull-up;       /* in modules/hal/stm32/dts/st/f4/stm32f427v(g-i)tx-pinctrl.dtsi:1933 */
				phandle = < 0x5 >;  /* in zephyr/boards/mikroe/quail/mikroe_quail.dts:229 */
			};

			/* node '/soc/pin-controller@40020000/usart2_tx_pd5' defined in modules/hal/stm32/dts/st/f4/stm32f427v(g-i)tx-pinctrl.dtsi:1946 */
			usart2_tx_pd5: usart2_tx_pd5 {
				pinmux = < 0x6a7 >; /* in modules/hal/stm32/dts/st/f4/stm32f427v(g-i)tx-pinctrl.dtsi:1947 */
				bias-pull-up;       /* in modules/hal/stm32/dts/st/f4/stm32f427v(g-i)tx-pinctrl.dtsi:1948 */
				phandle = < 0x7 >;  /* in zephyr/boards/mikroe/quail/mikroe_quail.dts:236 */
			};

			/* node '/soc/pin-controller@40020000/usart3_tx_pd8' defined in modules/hal/stm32/dts/st/f4/stm32f427v(g-i)tx-pinctrl.dtsi:1961 */
			usart3_tx_pd8: usart3_tx_pd8 {
				pinmux = < 0x707 >; /* in modules/hal/stm32/dts/st/f4/stm32f427v(g-i)tx-pinctrl.dtsi:1962 */
				bias-pull-up;       /* in modules/hal/stm32/dts/st/f4/stm32f427v(g-i)tx-pinctrl.dtsi:1963 */
				phandle = < 0x20 >; /* in zephyr/boards/mikroe/quail/mikroe_quail.dts:243 */
			};

			/* node '/soc/pin-controller@40020000/usart6_tx_pc6' defined in modules/hal/stm32/dts/st/f4/stm32f427v(g-i)tx-pinctrl.dtsi:1981 */
			usart6_tx_pc6: usart6_tx_pc6 {
				pinmux = < 0x4c8 >; /* in modules/hal/stm32/dts/st/f4/stm32f427v(g-i)tx-pinctrl.dtsi:1982 */
				bias-pull-up;       /* in modules/hal/stm32/dts/st/f4/stm32f427v(g-i)tx-pinctrl.dtsi:1983 */
				phandle = < 0x9 >;  /* in zephyr/boards/mikroe/quail/mikroe_quail.dts:250 */
			};

			/* node '/soc/pin-controller@40020000/usb_otg_fs_dm_pa11' defined in modules/hal/stm32/dts/st/f4/stm32f427v(g-i)tx-pinctrl.dtsi:2010 */
			usb_otg_fs_dm_pa11: usb_otg_fs_dm_pa11 {
				pinmux = < 0x16a >; /* in modules/hal/stm32/dts/st/f4/stm32f427v(g-i)tx-pinctrl.dtsi:2011 */
				phandle = < 0x16 >; /* in zephyr/boards/mikroe/quail/mikroe_quail.dts:263 */
			};

			/* node '/soc/pin-controller@40020000/usb_otg_fs_dp_pa12' defined in modules/hal/stm32/dts/st/f4/stm32f427v(g-i)tx-pinctrl.dtsi:2014 */
			usb_otg_fs_dp_pa12: usb_otg_fs_dp_pa12 {
				pinmux = < 0x18a >; /* in modules/hal/stm32/dts/st/f4/stm32f427v(g-i)tx-pinctrl.dtsi:2015 */
				phandle = < 0x17 >; /* in zephyr/boards/mikroe/quail/mikroe_quail.dts:263 */
			};
		};

		/* node '/soc/watchdog@40003000' defined in zephyr/dts/arm/st/f4/stm32f4.dtsi:277 */
		iwdg: watchdog@40003000 {
			compatible = "st,stm32-watchdog"; /* in zephyr/dts/arm/st/f4/stm32f4.dtsi:278 */
			reg = < 0x40003000 0x400 >;       /* in zephyr/dts/arm/st/f4/stm32f4.dtsi:279 */
			status = "disabled";              /* in zephyr/dts/arm/st/f4/stm32f4.dtsi:280 */
		};

		/* node '/soc/watchdog@40002c00' defined in zephyr/dts/arm/st/f4/stm32f4.dtsi:283 */
		wwdg: watchdog@40002c00 {
			compatible = "st,stm32-window-watchdog"; /* in zephyr/dts/arm/st/f4/stm32f4.dtsi:284 */
			reg = < 0x40002c00 0x400 >;              /* in zephyr/dts/arm/st/f4/stm32f4.dtsi:285 */
			clocks = < &rcc 0x40 0x800 >;            /* in zephyr/dts/arm/st/f4/stm32f4.dtsi:286 */
			interrupts = < 0x0 0x0 >;                /* in zephyr/dts/arm/st/f4/stm32f4.dtsi:287 */
			status = "disabled";                     /* in zephyr/dts/arm/st/f4/stm32f4.dtsi:288 */
		};

		/* node '/soc/serial@40011000' defined in zephyr/dts/arm/st/f4/stm32f4.dtsi:291 */
		usart1: mikrobus_4_uart: serial@40011000 {
			compatible = "st,stm32-usart",
			             "st,stm32-uart";                   /* in zephyr/dts/arm/st/f4/stm32f4.dtsi:292 */
			reg = < 0x40011000 0x400 >;                     /* in zephyr/dts/arm/st/f4/stm32f4.dtsi:293 */
			clocks = < &rcc 0x44 0x10 >;                    /* in zephyr/dts/arm/st/f4/stm32f4.dtsi:294 */
			resets = < &rctl 0x484 >;                       /* in zephyr/dts/arm/st/f4/stm32f4.dtsi:295 */
			interrupts = < 0x25 0x0 >;                      /* in zephyr/dts/arm/st/f4/stm32f4.dtsi:296 */
			pinctrl-0 = < &usart1_tx_pa9 &usart1_rx_pa10 >; /* in zephyr/boards/mikroe/quail/mikroe_quail.dts:229 */
			pinctrl-names = "default";                      /* in zephyr/boards/mikroe/quail/mikroe_quail.dts:230 */
			current-speed = < 0x1c200 >;                    /* in zephyr/boards/mikroe/quail/mikroe_quail.dts:231 */
			status = "okay";                                /* in zephyr/boards/mikroe/quail/mikroe_quail.dts:232 */
			phandle = < 0x37 >;                             /* in btr-shields/boards/extend/mikroe/quail/mikrobus_sockets.dtsi:118 */
		};

		/* node '/soc/serial@40004400' defined in zephyr/dts/arm/st/f4/stm32f4.dtsi:300 */
		usart2: mikrobus_2_uart: serial@40004400 {
			compatible = "st,stm32-usart",
			             "st,stm32-uart";                  /* in zephyr/dts/arm/st/f4/stm32f4.dtsi:301 */
			reg = < 0x40004400 0x400 >;                    /* in zephyr/dts/arm/st/f4/stm32f4.dtsi:302 */
			clocks = < &rcc 0x40 0x20000 >;                /* in zephyr/dts/arm/st/f4/stm32f4.dtsi:303 */
			resets = < &rctl 0x411 >;                      /* in zephyr/dts/arm/st/f4/stm32f4.dtsi:304 */
			interrupts = < 0x26 0x0 >;                     /* in zephyr/dts/arm/st/f4/stm32f4.dtsi:305 */
			pinctrl-0 = < &usart2_tx_pd5 &usart2_rx_pd6 >; /* in zephyr/boards/mikroe/quail/mikroe_quail.dts:236 */
			pinctrl-names = "default";                     /* in zephyr/boards/mikroe/quail/mikroe_quail.dts:237 */
			current-speed = < 0x1c200 >;                   /* in zephyr/boards/mikroe/quail/mikroe_quail.dts:238 */
			status = "okay";                               /* in zephyr/boards/mikroe/quail/mikroe_quail.dts:239 */
			phandle = < 0x34 >;                            /* in btr-shields/boards/extend/mikroe/quail/mikrobus_sockets.dtsi:74 */
		};

		/* node '/soc/serial@40011400' defined in zephyr/dts/arm/st/f4/stm32f4.dtsi:309 */
		usart6: mikrobus_3_uart: serial@40011400 {
			compatible = "st,stm32-usart",
			             "st,stm32-uart";                  /* in zephyr/dts/arm/st/f4/stm32f4.dtsi:310 */
			reg = < 0x40011400 0x400 >;                    /* in zephyr/dts/arm/st/f4/stm32f4.dtsi:311 */
			clocks = < &rcc 0x44 0x20 >;                   /* in zephyr/dts/arm/st/f4/stm32f4.dtsi:312 */
			resets = < &rctl 0x485 >;                      /* in zephyr/dts/arm/st/f4/stm32f4.dtsi:313 */
			interrupts = < 0x47 0x0 >;                     /* in zephyr/dts/arm/st/f4/stm32f4.dtsi:314 */
			pinctrl-0 = < &usart6_tx_pc6 &usart6_rx_pc7 >; /* in zephyr/boards/mikroe/quail/mikroe_quail.dts:250 */
			pinctrl-names = "default";                     /* in zephyr/boards/mikroe/quail/mikroe_quail.dts:251 */
			current-speed = < 0x1c200 >;                   /* in zephyr/boards/mikroe/quail/mikroe_quail.dts:252 */
			status = "okay";                               /* in zephyr/boards/mikroe/quail/mikroe_quail.dts:253 */
			phandle = < 0x36 >;                            /* in btr-shields/boards/extend/mikroe/quail/mikrobus_sockets.dtsi:96 */
		};

		/* node '/soc/i2c@40005400' defined in zephyr/dts/arm/st/f4/stm32f4.dtsi:318 */
		i2c1: mikrobus_1_i2c: mikrobus_2_i2c: mikrobus_3_i2c: mikrobus_4_i2c: mikrobus_i2c: i2c@40005400 {
			compatible = "st,stm32-i2c-v1";              /* in zephyr/dts/arm/st/f4/stm32f4.dtsi:319 */
			clock-frequency = < 0x186a0 >;               /* in zephyr/dts/arm/st/f4/stm32f4.dtsi:320 */
			#address-cells = < 0x1 >;                    /* in zephyr/dts/arm/st/f4/stm32f4.dtsi:321 */
			#size-cells = < 0x0 >;                       /* in zephyr/dts/arm/st/f4/stm32f4.dtsi:322 */
			reg = < 0x40005400 0x400 >;                  /* in zephyr/dts/arm/st/f4/stm32f4.dtsi:323 */
			clocks = < &rcc 0x40 0x200000 >;             /* in zephyr/dts/arm/st/f4/stm32f4.dtsi:324 */
			interrupts = < 0x1f 0x0 >,
			             < 0x20 0x0 >;                   /* in zephyr/dts/arm/st/f4/stm32f4.dtsi:325 */
			interrupt-names = "event",
			                  "error";                   /* in zephyr/dts/arm/st/f4/stm32f4.dtsi:326 */
			pinctrl-0 = < &i2c1_scl_pb6 &i2c1_sda_pb7 >; /* in zephyr/boards/mikroe/quail/mikroe_quail.dts:304 */
			pinctrl-names = "default";                   /* in zephyr/boards/mikroe/quail/mikroe_quail.dts:305 */
			scl-gpios = < &gpiob 0x6 0x0 >;              /* in zephyr/boards/mikroe/quail/mikroe_quail.dts:306 */
			sda-gpios = < &gpiob 0x7 0x0 >;              /* in zephyr/boards/mikroe/quail/mikroe_quail.dts:307 */
			status = "okay";                             /* in zephyr/boards/mikroe/quail/mikroe_quail.dts:308 */
			phandle = < 0x2c >;                          /* in zephyr/dts/arm/st/f4/stm32f4.dtsi:708 */

			/* node '/soc/i2c@40005400/sensor@48' defined in <RIGC_BUILD>/rig/rig-gen.overlay:6 */
			temp_a_tc_sensor: sensor@48 {
				compatible = "vnd,temp1234";          /* in <RIGC_BUILD>/rig/rig-gen.overlay:7 */
				reg = < 0x48 >;                       /* in <RIGC_BUILD>/rig/rig-gen.overlay:8 */
				int-gpios = < &quail_sock3 0x7 0x1 >; /* in <RIGC_BUILD>/rig/rig-gen.overlay:9 */
				status = "okay";                      /* in <RIGC_BUILD>/rig/rig-gen.overlay:10 */
			};

			/* node '/soc/i2c@40005400/sensor@49' defined in <RIGC_BUILD>/rig/rig-gen.overlay:12 */
			temp_b_tc_sensor: sensor@49 {
				compatible = "vnd,temp1234";          /* in <RIGC_BUILD>/rig/rig-gen.overlay:13 */
				reg = < 0x49 >;                       /* in <RIGC_BUILD>/rig/rig-gen.overlay:14 */
				int-gpios = < &quail_sock4 0x7 0x1 >; /* in <RIGC_BUILD>/rig/rig-gen.overlay:15 */
				status = "okay";                      /* in <RIGC_BUILD>/rig/rig-gen.overlay:16 */
			};
		};

		/* node '/soc/i2c@40005800' defined in zephyr/dts/arm/st/f4/stm32f4.dtsi:330 */
		i2c2: i2c@40005800 {
			compatible = "st,stm32-i2c-v1";  /* in zephyr/dts/arm/st/f4/stm32f4.dtsi:331 */
			clock-frequency = < 0x186a0 >;   /* in zephyr/dts/arm/st/f4/stm32f4.dtsi:332 */
			#address-cells = < 0x1 >;        /* in zephyr/dts/arm/st/f4/stm32f4.dtsi:333 */
			#size-cells = < 0x0 >;           /* in zephyr/dts/arm/st/f4/stm32f4.dtsi:334 */
			reg = < 0x40005800 0x400 >;      /* in zephyr/dts/arm/st/f4/stm32f4.dtsi:335 */
			clocks = < &rcc 0x40 0x400000 >; /* in zephyr/dts/arm/st/f4/stm32f4.dtsi:336 */
			interrupts = < 0x21 0x0 >,
			             < 0x22 0x0 >;       /* in zephyr/dts/arm/st/f4/stm32f4.dtsi:337 */
			interrupt-names = "event",
			                  "error";       /* in zephyr/dts/arm/st/f4/stm32f4.dtsi:338 */
			status = "disabled";             /* in zephyr/dts/arm/st/f4/stm32f4.dtsi:339 */
			phandle = < 0x2d >;              /* in zephyr/dts/arm/st/f4/stm32f4.dtsi:716 */
		};

		/* node '/soc/i2c@40005c00' defined in zephyr/dts/arm/st/f4/stm32f4.dtsi:342 */
		i2c3: i2c@40005c00 {
			compatible = "st,stm32-i2c-v1";  /* in zephyr/dts/arm/st/f4/stm32f4.dtsi:343 */
			clock-frequency = < 0x186a0 >;   /* in zephyr/dts/arm/st/f4/stm32f4.dtsi:344 */
			#address-cells = < 0x1 >;        /* in zephyr/dts/arm/st/f4/stm32f4.dtsi:345 */
			#size-cells = < 0x0 >;           /* in zephyr/dts/arm/st/f4/stm32f4.dtsi:346 */
			reg = < 0x40005c00 0x400 >;      /* in zephyr/dts/arm/st/f4/stm32f4.dtsi:347 */
			clocks = < &rcc 0x40 0x800000 >; /* in zephyr/dts/arm/st/f4/stm32f4.dtsi:348 */
			interrupts = < 0x48 0x0 >,
			             < 0x49 0x0 >;       /* in zephyr/dts/arm/st/f4/stm32f4.dtsi:349 */
			interrupt-names = "event",
			                  "error";       /* in zephyr/dts/arm/st/f4/stm32f4.dtsi:350 */
			status = "disabled";             /* in zephyr/dts/arm/st/f4/stm32f4.dtsi:351 */
			phandle = < 0x2e >;              /* in zephyr/dts/arm/st/f4/stm32f4.dtsi:724 */
		};

		/* node '/soc/spi@40013000' defined in zephyr/dts/arm/st/f4/stm32f4.dtsi:354 */
		spi1: mikrobus_1_spi: mikrobus_2_spi: mikrobus_spi: spi@40013000 {
			compatible = "st,stm32-spi";                                 /* in zephyr/dts/arm/st/f4/stm32f4.dtsi:355 */
			#address-cells = < 0x1 >;                                    /* in zephyr/dts/arm/st/f4/stm32f4.dtsi:356 */
			#size-cells = < 0x0 >;                                       /* in zephyr/dts/arm/st/f4/stm32f4.dtsi:357 */
			reg = < 0x40013000 0x400 >;                                  /* in zephyr/dts/arm/st/f4/stm32f4.dtsi:358 */
			clocks = < &rcc 0x44 0x1000 >;                               /* in zephyr/dts/arm/st/f4/stm32f4.dtsi:359 */
			interrupts = < 0x23 0x0 >;                                   /* in zephyr/dts/arm/st/f4/stm32f4.dtsi:360 */
			st,spi-data-width = "limited-8-16-bit";                      /* in zephyr/dts/arm/st/f4/stm32f4.dtsi:361 */
			pinctrl-0 = < &spi1_sck_pb3 &spi1_miso_pb4 &spi1_mosi_pb5 >; /* in zephyr/boards/mikroe/quail/mikroe_quail.dts:271 */
			pinctrl-names = "default";                                   /* in zephyr/boards/mikroe/quail/mikroe_quail.dts:272 */
			status = "okay";                                             /* in zephyr/boards/mikroe/quail/mikroe_quail.dts:274 */
			cs-gpios = < &quail_sock1 0x2 0x1 >,
			           < &quail_sock2 0x2 0x1 >;                         /* in <RIGC_BUILD>/rig/rig-gen.overlay:21 */
			phandle = < 0x32 >;                                          /* in btr-shields/boards/extend/mikroe/quail/mikrobus_sockets.dtsi:50 */

			/* node '/soc/spi@40013000/nor@0' defined in <RIGC_BUILD>/rig/rig-gen.overlay:22 */
			flash_a_fc_nor: nor@0 {
				compatible = "jedec,spi-nor";     /* in <RIGC_BUILD>/rig/rig-gen.overlay:23 */
				spi-max-frequency = < 0x7a1200 >; /* in <RIGC_BUILD>/rig/rig-gen.overlay:24 */
				jedec-id = [ C8 40 15 ];          /* in <RIGC_BUILD>/rig/rig-gen.overlay:25 */
				size = < 0x400000 >;              /* in <RIGC_BUILD>/rig/rig-gen.overlay:26 */
				reg = < 0x0 >;                    /* in <RIGC_BUILD>/rig/rig-gen.overlay:27 */
				status = "okay";                  /* in <RIGC_BUILD>/rig/rig-gen.overlay:28 */
			};

			/* node '/soc/spi@40013000/nor@1' defined in <RIGC_BUILD>/rig/rig-gen.overlay:30 */
			flash_b_fc_nor: nor@1 {
				compatible = "jedec,spi-nor";     /* in <RIGC_BUILD>/rig/rig-gen.overlay:31 */
				spi-max-frequency = < 0x7a1200 >; /* in <RIGC_BUILD>/rig/rig-gen.overlay:32 */
				jedec-id = [ C8 40 15 ];          /* in <RIGC_BUILD>/rig/rig-gen.overlay:33 */
				size = < 0x400000 >;              /* in <RIGC_BUILD>/rig/rig-gen.overlay:34 */
				reg = < 0x1 >;                    /* in <RIGC_BUILD>/rig/rig-gen.overlay:35 */
				status = "okay";                  /* in <RIGC_BUILD>/rig/rig-gen.overlay:36 */
			};
		};

		/* node '/soc/usb@50000000' defined in zephyr/dts/arm/st/f4/stm32f4.dtsi:365 */
		usbotg_fs: zephyr_udc0: usb@50000000 {
			compatible = "st,stm32-otgfs";                           /* in zephyr/dts/arm/st/f4/stm32f4.dtsi:366 */
			reg = < 0x50000000 0x40000 >;                            /* in zephyr/dts/arm/st/f4/stm32f4.dtsi:367 */
			interrupts = < 0x43 0x0 >;                               /* in zephyr/dts/arm/st/f4/stm32f4.dtsi:368 */
			interrupt-names = "otgfs";                               /* in zephyr/dts/arm/st/f4/stm32f4.dtsi:369 */
			num-bidir-endpoints = < 0x4 >;                           /* in zephyr/dts/arm/st/f4/stm32f4.dtsi:370 */
			ram-size = < 0x500 >;                                    /* in zephyr/dts/arm/st/f4/stm32f4.dtsi:371 */
			maximum-speed = "full-speed";                            /* in zephyr/dts/arm/st/f4/stm32f4.dtsi:372 */
			phys = < &otgfs_phy >;                                   /* in zephyr/dts/arm/st/f4/stm32f4.dtsi:373 */
			clocks = < &rcc 0x34 0x80 >,
			         < &rcc 0x7 0xff >;                              /* in zephyr/dts/arm/st/f4/stm32f4.dtsi:374 */
			pinctrl-0 = < &usb_otg_fs_dm_pa11 &usb_otg_fs_dp_pa12 >; /* in zephyr/boards/mikroe/quail/mikroe_quail.dts:263 */
			pinctrl-names = "default";                               /* in zephyr/boards/mikroe/quail/mikroe_quail.dts:264 */
			status = "okay";                                         /* in zephyr/boards/mikroe/quail/mikroe_quail.dts:265 */

			/* node '/soc/usb@50000000/board_cdc_acm_uart' defined in zephyr/boards/common/usb/cdc_acm_serial.dtsi:18 */
			board_cdc_acm_uart: board_cdc_acm_uart {
				compatible = "zephyr,cdc-acm-uart"; /* in zephyr/boards/common/usb/cdc_acm_serial.dtsi:19 */
			};
		};

		/* node '/soc/timers@40010000' defined in zephyr/dts/arm/st/f4/stm32f4.dtsi:379 */
		timers1: timers@40010000 {
			compatible = "st,stm32-timers"; /* in zephyr/dts/arm/st/f4/stm32f4.dtsi:380 */
			reg = < 0x40010000 0x400 >;     /* in zephyr/dts/arm/st/f4/stm32f4.dtsi:381 */
			clocks = < &rcc 0x44 0x1 >,
			         < &rcc 0x16 0xff >;    /* in zephyr/dts/arm/st/f4/stm32f4.dtsi:382 */
			resets = < &rctl 0x480 >;       /* in zephyr/dts/arm/st/f4/stm32f4.dtsi:384 */
			interrupts = < 0x18 0x0 >,
			             < 0x19 0x0 >,
			             < 0x1a 0x0 >,
			             < 0x1b 0x0 >;      /* in zephyr/dts/arm/st/f4/stm32f4.dtsi:385 */
			interrupt-names = "brk",
			                  "up",
			                  "trgcom",
			                  "cc";         /* in zephyr/dts/arm/st/f4/stm32f4.dtsi:386 */
			st,prescaler = < 0x0 >;         /* in zephyr/dts/arm/st/f4/stm32f4.dtsi:387 */
			status = "disabled";            /* in zephyr/dts/arm/st/f4/stm32f4.dtsi:388 */

			/* node '/soc/timers@40010000/pwm' defined in zephyr/dts/arm/st/f4/stm32f4.dtsi:390 */
			pwm {
				compatible = "st,stm32-pwm"; /* in zephyr/dts/arm/st/f4/stm32f4.dtsi:391 */
				status = "disabled";         /* in zephyr/dts/arm/st/f4/stm32f4.dtsi:392 */
				#pwm-cells = < 0x3 >;        /* in zephyr/dts/arm/st/f4/stm32f4.dtsi:393 */
			};

			/* node '/soc/timers@40010000/counter' defined in zephyr/dts/arm/st/f4/stm32f4.dtsi:396 */
			counter {
				compatible = "st,stm32-counter"; /* in zephyr/dts/arm/st/f4/stm32f4.dtsi:397 */
				status = "disabled";             /* in zephyr/dts/arm/st/f4/stm32f4.dtsi:398 */
			};

			/* node '/soc/timers@40010000/qdec' defined in zephyr/dts/arm/st/f4/stm32f4.dtsi:401 */
			qdec {
				compatible = "st,stm32-qdec";    /* in zephyr/dts/arm/st/f4/stm32f4.dtsi:402 */
				st,input-filter-level = < 0x0 >; /* in zephyr/dts/arm/st/f4/stm32f4.dtsi:403 */
				status = "disabled";             /* in zephyr/dts/arm/st/f4/stm32f4.dtsi:404 */
			};
		};

		/* node '/soc/timers@40000000' defined in zephyr/dts/arm/st/f4/stm32f4.dtsi:408 */
		timers2: timers@40000000 {
			compatible = "st,stm32-timers"; /* in zephyr/dts/arm/st/f4/stm32f4.dtsi:409 */
			reg = < 0x40000000 0x400 >;     /* in zephyr/dts/arm/st/f4/stm32f4.dtsi:410 */
			clocks = < &rcc 0x40 0x1 >,
			         < &rcc 0x15 0xff >;    /* in zephyr/dts/arm/st/f4/stm32f4.dtsi:411 */
			resets = < &rctl 0x400 >;       /* in zephyr/dts/arm/st/f4/stm32f4.dtsi:413 */
			interrupts = < 0x1c 0x0 >;      /* in zephyr/dts/arm/st/f4/stm32f4.dtsi:414 */
			interrupt-names = "global";     /* in zephyr/dts/arm/st/f4/stm32f4.dtsi:415 */
			st,prescaler = < 0x0 >;         /* in zephyr/dts/arm/st/f4/stm32f4.dtsi:416 */
			status = "disabled";            /* in zephyr/dts/arm/st/f4/stm32f4.dtsi:417 */

			/* node '/soc/timers@40000000/pwm' defined in zephyr/dts/arm/st/f4/stm32f4.dtsi:419 */
			pwm {
				compatible = "st,stm32-pwm"; /* in zephyr/dts/arm/st/f4/stm32f4.dtsi:420 */
				status = "disabled";         /* in zephyr/dts/arm/st/f4/stm32f4.dtsi:421 */
				#pwm-cells = < 0x3 >;        /* in zephyr/dts/arm/st/f4/stm32f4.dtsi:422 */
			};

			/* node '/soc/timers@40000000/counter' defined in zephyr/dts/arm/st/f4/stm32f4.dtsi:425 */
			counter {
				compatible = "st,stm32-counter"; /* in zephyr/dts/arm/st/f4/stm32f4.dtsi:426 */
				status = "disabled";             /* in zephyr/dts/arm/st/f4/stm32f4.dtsi:427 */
			};

			/* node '/soc/timers@40000000/qdec' defined in zephyr/dts/arm/st/f4/stm32f4.dtsi:430 */
			qdec {
				compatible = "st,stm32-qdec";    /* in zephyr/dts/arm/st/f4/stm32f4.dtsi:431 */
				st,input-filter-level = < 0x0 >; /* in zephyr/dts/arm/st/f4/stm32f4.dtsi:432 */
				status = "disabled";             /* in zephyr/dts/arm/st/f4/stm32f4.dtsi:433 */
			};
		};

		/* node '/soc/timers@40000400' defined in zephyr/dts/arm/st/f4/stm32f4.dtsi:437 */
		timers3: timers@40000400 {
			compatible = "st,stm32-timers"; /* in zephyr/dts/arm/st/f4/stm32f4.dtsi:438 */
			reg = < 0x40000400 0x400 >;     /* in zephyr/dts/arm/st/f4/stm32f4.dtsi:439 */
			clocks = < &rcc 0x40 0x2 >,
			         < &rcc 0x15 0xff >;    /* in zephyr/dts/arm/st/f4/stm32f4.dtsi:440 */
			resets = < &rctl 0x401 >;       /* in zephyr/dts/arm/st/f4/stm32f4.dtsi:442 */
			interrupts = < 0x1d 0x0 >;      /* in zephyr/dts/arm/st/f4/stm32f4.dtsi:443 */
			interrupt-names = "global";     /* in zephyr/dts/arm/st/f4/stm32f4.dtsi:444 */
			st,prescaler = < 0x0 >;         /* in zephyr/dts/arm/st/f4/stm32f4.dtsi:445 */
			status = "disabled";            /* in zephyr/dts/arm/st/f4/stm32f4.dtsi:446 */

			/* node '/soc/timers@40000400/pwm' defined in zephyr/dts/arm/st/f4/stm32f4.dtsi:448 */
			pwm {
				compatible = "st,stm32-pwm"; /* in zephyr/dts/arm/st/f4/stm32f4.dtsi:449 */
				status = "disabled";         /* in zephyr/dts/arm/st/f4/stm32f4.dtsi:450 */
				#pwm-cells = < 0x3 >;        /* in zephyr/dts/arm/st/f4/stm32f4.dtsi:451 */
			};

			/* node '/soc/timers@40000400/counter' defined in zephyr/dts/arm/st/f4/stm32f4.dtsi:454 */
			counter {
				compatible = "st,stm32-counter"; /* in zephyr/dts/arm/st/f4/stm32f4.dtsi:455 */
				status = "disabled";             /* in zephyr/dts/arm/st/f4/stm32f4.dtsi:456 */
			};

			/* node '/soc/timers@40000400/qdec' defined in zephyr/dts/arm/st/f4/stm32f4.dtsi:459 */
			qdec {
				compatible = "st,stm32-qdec";    /* in zephyr/dts/arm/st/f4/stm32f4.dtsi:460 */
				st,input-filter-level = < 0x0 >; /* in zephyr/dts/arm/st/f4/stm32f4.dtsi:461 */
				status = "disabled";             /* in zephyr/dts/arm/st/f4/stm32f4.dtsi:462 */
			};
		};

		/* node '/soc/timers@40000800' defined in zephyr/dts/arm/st/f4/stm32f4.dtsi:466 */
		timers4: timers@40000800 {
			compatible = "st,stm32-timers"; /* in zephyr/dts/arm/st/f4/stm32f4.dtsi:467 */
			reg = < 0x40000800 0x400 >;     /* in zephyr/dts/arm/st/f4/stm32f4.dtsi:468 */
			clocks = < &rcc 0x40 0x4 >,
			         < &rcc 0x15 0xff >;    /* in zephyr/dts/arm/st/f4/stm32f4.dtsi:469 */
			resets = < &rctl 0x402 >;       /* in zephyr/dts/arm/st/f4/stm32f4.dtsi:471 */
			interrupts = < 0x1e 0x0 >;      /* in zephyr/dts/arm/st/f4/stm32f4.dtsi:472 */
			interrupt-names = "global";     /* in zephyr/dts/arm/st/f4/stm32f4.dtsi:473 */
			st,prescaler = < 0x0 >;         /* in zephyr/dts/arm/st/f4/stm32f4.dtsi:474 */
			status = "disabled";            /* in zephyr/dts/arm/st/f4/stm32f4.dtsi:475 */

			/* node '/soc/timers@40000800/pwm' defined in zephyr/dts/arm/st/f4/stm32f4.dtsi:477 */
			pwm {
				compatible = "st,stm32-pwm"; /* in zephyr/dts/arm/st/f4/stm32f4.dtsi:478 */
				status = "disabled";         /* in zephyr/dts/arm/st/f4/stm32f4.dtsi:479 */
				#pwm-cells = < 0x3 >;        /* in zephyr/dts/arm/st/f4/stm32f4.dtsi:480 */
			};

			/* node '/soc/timers@40000800/counter' defined in zephyr/dts/arm/st/f4/stm32f4.dtsi:483 */
			counter {
				compatible = "st,stm32-counter"; /* in zephyr/dts/arm/st/f4/stm32f4.dtsi:484 */
				status = "disabled";             /* in zephyr/dts/arm/st/f4/stm32f4.dtsi:485 */
			};

			/* node '/soc/timers@40000800/qdec' defined in zephyr/dts/arm/st/f4/stm32f4.dtsi:488 */
			qdec {
				compatible = "st,stm32-qdec";    /* in zephyr/dts/arm/st/f4/stm32f4.dtsi:489 */
				st,input-filter-level = < 0x0 >; /* in zephyr/dts/arm/st/f4/stm32f4.dtsi:490 */
				status = "disabled";             /* in zephyr/dts/arm/st/f4/stm32f4.dtsi:491 */
			};
		};

		/* node '/soc/timers@40000c00' defined in zephyr/dts/arm/st/f4/stm32f4.dtsi:495 */
		timers5: timers@40000c00 {
			compatible = "st,stm32-timers"; /* in zephyr/dts/arm/st/f4/stm32f4.dtsi:496 */
			reg = < 0x40000c00 0x400 >;     /* in zephyr/dts/arm/st/f4/stm32f4.dtsi:497 */
			clocks = < &rcc 0x40 0x8 >,
			         < &rcc 0x15 0xff >;    /* in zephyr/dts/arm/st/f4/stm32f4.dtsi:498 */
			resets = < &rctl 0x403 >;       /* in zephyr/dts/arm/st/f4/stm32f4.dtsi:500 */
			interrupts = < 0x32 0x0 >;      /* in zephyr/dts/arm/st/f4/stm32f4.dtsi:501 */
			interrupt-names = "global";     /* in zephyr/dts/arm/st/f4/stm32f4.dtsi:502 */
			st,prescaler = < 0x0 >;         /* in zephyr/dts/arm/st/f4/stm32f4.dtsi:503 */
			status = "disabled";            /* in zephyr/dts/arm/st/f4/stm32f4.dtsi:504 */

			/* node '/soc/timers@40000c00/pwm' defined in zephyr/dts/arm/st/f4/stm32f4.dtsi:506 */
			pwm {
				compatible = "st,stm32-pwm"; /* in zephyr/dts/arm/st/f4/stm32f4.dtsi:507 */
				status = "disabled";         /* in zephyr/dts/arm/st/f4/stm32f4.dtsi:508 */
				#pwm-cells = < 0x3 >;        /* in zephyr/dts/arm/st/f4/stm32f4.dtsi:509 */
			};

			/* node '/soc/timers@40000c00/counter' defined in zephyr/dts/arm/st/f4/stm32f4.dtsi:512 */
			counter {
				compatible = "st,stm32-counter"; /* in zephyr/dts/arm/st/f4/stm32f4.dtsi:513 */
				status = "disabled";             /* in zephyr/dts/arm/st/f4/stm32f4.dtsi:514 */
			};

			/* node '/soc/timers@40000c00/qdec' defined in zephyr/dts/arm/st/f4/stm32f4.dtsi:517 */
			qdec {
				compatible = "st,stm32-qdec";    /* in zephyr/dts/arm/st/f4/stm32f4.dtsi:518 */
				st,input-filter-level = < 0x0 >; /* in zephyr/dts/arm/st/f4/stm32f4.dtsi:519 */
				status = "disabled";             /* in zephyr/dts/arm/st/f4/stm32f4.dtsi:520 */
			};
		};

		/* node '/soc/timers@40014000' defined in zephyr/dts/arm/st/f4/stm32f4.dtsi:524 */
		timers9: timers@40014000 {
			compatible = "st,stm32-timers"; /* in zephyr/dts/arm/st/f4/stm32f4.dtsi:525 */
			reg = < 0x40014000 0x400 >;     /* in zephyr/dts/arm/st/f4/stm32f4.dtsi:526 */
			clocks = < &rcc 0x44 0x10000 >,
			         < &rcc 0x16 0xff >;    /* in zephyr/dts/arm/st/f4/stm32f4.dtsi:527 */
			resets = < &rctl 0x490 >;       /* in zephyr/dts/arm/st/f4/stm32f4.dtsi:529 */
			interrupts = < 0x18 0x0 >;      /* in zephyr/dts/arm/st/f4/stm32f4.dtsi:530 */
			interrupt-names = "global";     /* in zephyr/dts/arm/st/f4/stm32f4.dtsi:531 */
			st,prescaler = < 0x0 >;         /* in zephyr/dts/arm/st/f4/stm32f4.dtsi:532 */
			status = "disabled";            /* in zephyr/dts/arm/st/f4/stm32f4.dtsi:533 */

			/* node '/soc/timers@40014000/pwm' defined in zephyr/dts/arm/st/f4/stm32f4.dtsi:535 */
			pwm {
				compatible = "st,stm32-pwm"; /* in zephyr/dts/arm/st/f4/stm32f4.dtsi:536 */
				status = "disabled";         /* in zephyr/dts/arm/st/f4/stm32f4.dtsi:537 */
				#pwm-cells = < 0x3 >;        /* in zephyr/dts/arm/st/f4/stm32f4.dtsi:538 */
			};

			/* node '/soc/timers@40014000/counter' defined in zephyr/dts/arm/st/f4/stm32f4.dtsi:541 */
			counter {
				compatible = "st,stm32-counter"; /* in zephyr/dts/arm/st/f4/stm32f4.dtsi:542 */
				status = "disabled";             /* in zephyr/dts/arm/st/f4/stm32f4.dtsi:543 */
			};
		};

		/* node '/soc/timers@40014400' defined in zephyr/dts/arm/st/f4/stm32f4.dtsi:547 */
		timers10: timers@40014400 {
			compatible = "st,stm32-timers"; /* in zephyr/dts/arm/st/f4/stm32f4.dtsi:548 */
			reg = < 0x40014400 0x400 >;     /* in zephyr/dts/arm/st/f4/stm32f4.dtsi:549 */
			clocks = < &rcc 0x44 0x20000 >,
			         < &rcc 0x16 0xff >;    /* in zephyr/dts/arm/st/f4/stm32f4.dtsi:550 */
			resets = < &rctl 0x491 >;       /* in zephyr/dts/arm/st/f4/stm32f4.dtsi:552 */
			interrupts = < 0x19 0x0 >;      /* in zephyr/dts/arm/st/f4/stm32f4.dtsi:553 */
			interrupt-names = "global";     /* in zephyr/dts/arm/st/f4/stm32f4.dtsi:554 */
			st,prescaler = < 0x0 >;         /* in zephyr/dts/arm/st/f4/stm32f4.dtsi:555 */
			status = "disabled";            /* in zephyr/dts/arm/st/f4/stm32f4.dtsi:556 */

			/* node '/soc/timers@40014400/pwm' defined in zephyr/dts/arm/st/f4/stm32f4.dtsi:558 */
			pwm {
				compatible = "st,stm32-pwm"; /* in zephyr/dts/arm/st/f4/stm32f4.dtsi:559 */
				status = "disabled";         /* in zephyr/dts/arm/st/f4/stm32f4.dtsi:560 */
				#pwm-cells = < 0x3 >;        /* in zephyr/dts/arm/st/f4/stm32f4.dtsi:561 */
			};

			/* node '/soc/timers@40014400/counter' defined in zephyr/dts/arm/st/f4/stm32f4.dtsi:564 */
			counter {
				compatible = "st,stm32-counter"; /* in zephyr/dts/arm/st/f4/stm32f4.dtsi:565 */
				status = "disabled";             /* in zephyr/dts/arm/st/f4/stm32f4.dtsi:566 */
			};
		};

		/* node '/soc/timers@40014800' defined in zephyr/dts/arm/st/f4/stm32f4.dtsi:570 */
		timers11: timers@40014800 {
			compatible = "st,stm32-timers"; /* in zephyr/dts/arm/st/f4/stm32f4.dtsi:571 */
			reg = < 0x40014800 0x400 >;     /* in zephyr/dts/arm/st/f4/stm32f4.dtsi:572 */
			clocks = < &rcc 0x44 0x40000 >,
			         < &rcc 0x16 0xff >;    /* in zephyr/dts/arm/st/f4/stm32f4.dtsi:573 */
			resets = < &rctl 0x492 >;       /* in zephyr/dts/arm/st/f4/stm32f4.dtsi:575 */
			interrupts = < 0x1a 0x0 >;      /* in zephyr/dts/arm/st/f4/stm32f4.dtsi:576 */
			interrupt-names = "global";     /* in zephyr/dts/arm/st/f4/stm32f4.dtsi:577 */
			st,prescaler = < 0x0 >;         /* in zephyr/dts/arm/st/f4/stm32f4.dtsi:578 */
			status = "disabled";            /* in zephyr/dts/arm/st/f4/stm32f4.dtsi:579 */

			/* node '/soc/timers@40014800/pwm' defined in zephyr/dts/arm/st/f4/stm32f4.dtsi:581 */
			pwm {
				compatible = "st,stm32-pwm"; /* in zephyr/dts/arm/st/f4/stm32f4.dtsi:582 */
				status = "disabled";         /* in zephyr/dts/arm/st/f4/stm32f4.dtsi:583 */
				#pwm-cells = < 0x3 >;        /* in zephyr/dts/arm/st/f4/stm32f4.dtsi:584 */
			};

			/* node '/soc/timers@40014800/counter' defined in zephyr/dts/arm/st/f4/stm32f4.dtsi:587 */
			counter {
				compatible = "st,stm32-counter"; /* in zephyr/dts/arm/st/f4/stm32f4.dtsi:588 */
				status = "disabled";             /* in zephyr/dts/arm/st/f4/stm32f4.dtsi:589 */
			};
		};

		/* node '/soc/rtc@40002800' defined in zephyr/dts/arm/st/f4/stm32f4.dtsi:593 */
		rtc: rtc@40002800 {
			compatible = "st,stm32-rtc";       /* in zephyr/dts/arm/st/f4/stm32f4.dtsi:594 */
			reg = < 0x40002800 0x400 >;        /* in zephyr/dts/arm/st/f4/stm32f4.dtsi:595 */
			interrupts = < 0x29 0x0 >;         /* in zephyr/dts/arm/st/f4/stm32f4.dtsi:596 */
			prescaler = < 0x8000 >;            /* in zephyr/dts/arm/st/f4/stm32f4.dtsi:598 */
			alarms-count = < 0x2 >;            /* in zephyr/dts/arm/st/f4/stm32f4.dtsi:599 */
			alrm-exti-line = < 0x11 >;         /* in zephyr/dts/arm/st/f4/stm32f4.dtsi:600 */
			clocks = < &rcc 0x40 0x10000000 >,
			         < &rcc 0x3 0x2280070 >;   /* in zephyr/boards/mikroe/quail/mikroe_quail.dts:257 */
			status = "okay";                   /* in zephyr/boards/mikroe/quail/mikroe_quail.dts:259 */

			/* node '/soc/rtc@40002800/backup_regs' defined in zephyr/dts/arm/st/f4/stm32f4.dtsi:603 */
			bbram: backup_regs {
				compatible = "st,stm32-bbram"; /* in zephyr/dts/arm/st/f4/stm32f4.dtsi:604 */
				st,backup-regs = < 0x14 >;     /* in zephyr/dts/arm/st/f4/stm32f4.dtsi:605 */
				status = "disabled";           /* in zephyr/dts/arm/st/f4/stm32f4.dtsi:606 */
			};
		};

		/* node '/soc/adc@40012000' defined in zephyr/dts/arm/st/f4/stm32f4.dtsi:610 */
		adc1: adc@40012000 {
			compatible = "st,stm32f4-adc",
			             "st,stm32-adc";                                 /* in zephyr/dts/arm/st/f4/stm32f4.dtsi:611 */
			reg = < 0x40012000 0x400 >;                                  /* in zephyr/dts/arm/st/f4/stm32f4.dtsi:612 */
			clocks = < &rcc 0x44 0x100 >;                                /* in zephyr/dts/arm/st/f4/stm32f4.dtsi:613 */
			clock-names = "adcx";                                        /* in zephyr/dts/arm/st/f4/stm32f4.dtsi:614 */
			interrupts = < 0x12 0x0 >;                                   /* in zephyr/dts/arm/st/f4/stm32f4.dtsi:615 */
			#io-channel-cells = < 0x1 >;                                 /* in zephyr/dts/arm/st/f4/stm32f4.dtsi:616 */
			st,adc-resolutions = < 0xc 0xa 0x8 0x6 >;                    /* in zephyr/dts/arm/st/f4/stm32f4.dtsi:617 */
			sampling-times = < 0x3 0xf 0x1c 0x38 0x54 0x70 0x90 0x1e0 >; /* in zephyr/dts/arm/st/f4/stm32f4.dtsi:618 */
			st,adc-sequencer = "programmable";                           /* in zephyr/dts/arm/st/f4/stm32f4.dtsi:620 */
			st,adc-oversampler = "none";                                 /* in zephyr/dts/arm/st/f4/stm32f4.dtsi:621 */
			st,adc-internal-regulator = "none";                          /* in zephyr/dts/arm/st/f4/stm32f4.dtsi:622 */
			st,adc-has-injected-support;                                 /* in zephyr/dts/arm/st/f4/stm32f4.dtsi:623 */
			status = "okay";                                             /* in zephyr/boards/mikroe/quail/mikroe_quail.dts:312 */
			pinctrl-0 = < &adc1_in4_pa4 &adc1_in5_pa5 >;                 /* in zephyr/boards/mikroe/quail/mikroe_quail.dts:313 */
			pinctrl-names = "default";                                   /* in zephyr/boards/mikroe/quail/mikroe_quail.dts:314 */
			st,adc-clock-source = "SYNC";                                /* in zephyr/boards/mikroe/quail/mikroe_quail.dts:315 */
			st,adc-prescaler = < 0x2 >;                                  /* in zephyr/boards/mikroe/quail/mikroe_quail.dts:316 */
			phandle = < 0x2a >;                                          /* in zephyr/dts/arm/st/f4/stm32f427.dtsi:147 */
		};

		/* node '/soc/dma@40026000' defined in zephyr/dts/arm/st/f4/stm32f4.dtsi:627 */
		dma1: dma@40026000 {
			compatible = "st,stm32-dma-v1";                                                      /* in zephyr/dts/arm/st/f4/stm32f4.dtsi:628 */
			#dma-cells = < 0x4 >;                                                                /* in zephyr/dts/arm/st/f4/stm32f4.dtsi:629 */
			reg = < 0x40026000 0x400 >;                                                          /* in zephyr/dts/arm/st/f4/stm32f4.dtsi:630 */
			interrupts = < 0xb 0x0 0xc 0x0 0xd 0x0 0xe 0x0 0xf 0x0 0x10 0x0 0x11 0x0 0x2f 0x0 >; /* in zephyr/dts/arm/st/f4/stm32f4.dtsi:631 */
			clocks = < &rcc 0x30 0x200000 >;                                                     /* in zephyr/dts/arm/st/f4/stm32f4.dtsi:632 */
			status = "disabled";                                                                 /* in zephyr/dts/arm/st/f4/stm32f4.dtsi:633 */
			phandle = < 0x1f >;                                                                  /* in zephyr/dts/arm/st/f4/stm32f401.dtsi:61 */
		};

		/* node '/soc/dma@40026400' defined in zephyr/dts/arm/st/f4/stm32f4.dtsi:636 */
		dma2: dma@40026400 {
			compatible = "st,stm32-dma-v1";                                                           /* in zephyr/dts/arm/st/f4/stm32f4.dtsi:637 */
			#dma-cells = < 0x4 >;                                                                     /* in zephyr/dts/arm/st/f4/stm32f4.dtsi:638 */
			reg = < 0x40026400 0x400 >;                                                               /* in zephyr/dts/arm/st/f4/stm32f4.dtsi:639 */
			interrupts = < 0x38 0x0 0x39 0x0 0x3a 0x0 0x3b 0x0 0x3c 0x0 0x44 0x0 0x45 0x0 0x46 0x0 >; /* in zephyr/dts/arm/st/f4/stm32f4.dtsi:640 */
			clocks = < &rcc 0x30 0x400000 >;                                                          /* in zephyr/dts/arm/st/f4/stm32f4.dtsi:641 */
			st,mem2mem;                                                                               /* in zephyr/dts/arm/st/f4/stm32f4.dtsi:642 */
			status = "disabled";                                                                      /* in zephyr/dts/arm/st/f4/stm32f4.dtsi:643 */
			phandle = < 0x25 >;                                                                       /* in zephyr/dts/arm/st/f4/stm32f427.dtsi:130 */
		};

		/* node '/soc/sdmmc@40012c00' defined in zephyr/dts/arm/st/f4/stm32f4.dtsi:646 */
		sdmmc1: sdmmc@40012c00 {
			compatible = "st,stm32-sdmmc"; /* in zephyr/dts/arm/st/f4/stm32f4.dtsi:647 */
			reg = < 0x40012c00 0x400 >;    /* in zephyr/dts/arm/st/f4/stm32f4.dtsi:648 */
			clocks = < &rcc 0x44 0x800 >,
			         < &rcc 0x7 0xff >;    /* in zephyr/dts/arm/st/f4/stm32f4.dtsi:649 */
			resets = < &rctl 0x48b >;      /* in zephyr/dts/arm/st/f4/stm32f4.dtsi:651 */
			interrupts = < 0x31 0x0 >;     /* in zephyr/dts/arm/st/f4/stm32f4.dtsi:652 */
			status = "disabled";           /* in zephyr/dts/arm/st/f4/stm32f4.dtsi:653 */
		};

		/* node '/soc/spi@40003800' defined in zephyr/dts/arm/st/f4/stm32f401.dtsi:21 */
		spi2: spi@40003800 {
			compatible = "st,stm32-spi";            /* in zephyr/dts/arm/st/f4/stm32f401.dtsi:22 */
			#address-cells = < 0x1 >;               /* in zephyr/dts/arm/st/f4/stm32f401.dtsi:23 */
			#size-cells = < 0x0 >;                  /* in zephyr/dts/arm/st/f4/stm32f401.dtsi:24 */
			reg = < 0x40003800 0x400 >;             /* in zephyr/dts/arm/st/f4/stm32f401.dtsi:25 */
			clocks = < &rcc 0x40 0x4000 >;          /* in zephyr/dts/arm/st/f4/stm32f401.dtsi:26 */
			interrupts = < 0x24 0x0 >;              /* in zephyr/dts/arm/st/f4/stm32f401.dtsi:27 */
			st,spi-data-width = "limited-8-16-bit"; /* in zephyr/dts/arm/st/f4/stm32f401.dtsi:28 */
			status = "disabled";                    /* in zephyr/dts/arm/st/f4/stm32f401.dtsi:29 */
		};

		/* node '/soc/spi@40003c00' defined in zephyr/dts/arm/st/f4/stm32f401.dtsi:32 */
		spi3: mikrobus_3_spi: mikrobus_4_spi: spi@40003c00 {
			compatible = "st,stm32-spi";                                    /* in zephyr/dts/arm/st/f4/stm32f401.dtsi:33 */
			#address-cells = < 0x1 >;                                       /* in zephyr/dts/arm/st/f4/stm32f401.dtsi:34 */
			#size-cells = < 0x0 >;                                          /* in zephyr/dts/arm/st/f4/stm32f401.dtsi:35 */
			reg = < 0x40003c00 0x400 >;                                     /* in zephyr/dts/arm/st/f4/stm32f401.dtsi:36 */
			clocks = < &rcc 0x40 0x8000 >;                                  /* in zephyr/dts/arm/st/f4/stm32f401.dtsi:37 */
			interrupts = < 0x33 0x0 >;                                      /* in zephyr/dts/arm/st/f4/stm32f401.dtsi:38 */
			st,spi-data-width = "limited-8-16-bit";                         /* in zephyr/dts/arm/st/f4/stm32f401.dtsi:39 */
			status = "okay";                                                /* in zephyr/boards/mikroe/quail/mikroe_quail.dts:278 */
			pinctrl-0 = < &spi3_sck_pc10 &spi3_miso_pc11 &spi3_mosi_pc12 >; /* in zephyr/boards/mikroe/quail/mikroe_quail.dts:279 */
			pinctrl-names = "default";                                      /* in zephyr/boards/mikroe/quail/mikroe_quail.dts:280 */
			cs-gpios = < &gpiod 0xb 0x1 >,
			           < &gpiod 0x1 0x1 >,
			           < &gpioa 0xd 0x1 >;                                  /* in zephyr/boards/mikroe/quail/mikroe_quail.dts:282 */
			phandle = < 0x35 >;                                             /* in btr-shields/boards/extend/mikroe/quail/mikrobus_sockets.dtsi:94 */

			/* node '/soc/spi@40003c00/flash@2' defined in zephyr/boards/mikroe/quail/mikroe_quail.dts:289 */
			flash1: flash@2 {
				compatible = "jedec,spi-nor";      /* in zephyr/boards/mikroe/quail/mikroe_quail.dts:290 */
				reg = < 0x2 >;                     /* in zephyr/boards/mikroe/quail/mikroe_quail.dts:291 */
				jedec-id = [ 01 60 17 ];           /* in zephyr/boards/mikroe/quail/mikroe_quail.dts:295 */
				spi-max-frequency = < 0x2faf080 >; /* in zephyr/boards/mikroe/quail/mikroe_quail.dts:296 */
				size = < 0x800000 >;               /* in zephyr/boards/mikroe/quail/mikroe_quail.dts:297 */
				page-size = < 0x100 >;             /* in zephyr/boards/mikroe/quail/mikroe_quail.dts:298 */
				status = "okay";                   /* in zephyr/boards/mikroe/quail/mikroe_quail.dts:299 */
			};
		};

		/* node '/soc/spi@40013400' defined in zephyr/dts/arm/st/f4/stm32f401.dtsi:43 */
		spi4: spi@40013400 {
			compatible = "st,stm32-spi";            /* in zephyr/dts/arm/st/f4/stm32f427.dtsi:67 */
			#address-cells = < 0x1 >;               /* in zephyr/dts/arm/st/f4/stm32f427.dtsi:68 */
			#size-cells = < 0x0 >;                  /* in zephyr/dts/arm/st/f4/stm32f427.dtsi:69 */
			reg = < 0x40013400 0x400 >;             /* in zephyr/dts/arm/st/f4/stm32f427.dtsi:70 */
			clocks = < &rcc 0x44 0x2000 >;          /* in zephyr/dts/arm/st/f4/stm32f427.dtsi:71 */
			interrupts = < 0x54 0x0 >;              /* in zephyr/dts/arm/st/f4/stm32f427.dtsi:72 */
			st,spi-data-width = "limited-8-16-bit"; /* in zephyr/dts/arm/st/f4/stm32f427.dtsi:73 */
			status = "disabled";                    /* in zephyr/dts/arm/st/f4/stm32f427.dtsi:74 */
		};

		/* node '/soc/i2s@40003800' defined in zephyr/dts/arm/st/f4/stm32f401.dtsi:54 */
		i2s2: i2s@40003800 {
			compatible = "st,stm32-i2s";        /* in zephyr/dts/arm/st/f4/stm32f401.dtsi:55 */
			#address-cells = < 0x1 >;           /* in zephyr/dts/arm/st/f4/stm32f401.dtsi:56 */
			#size-cells = < 0x0 >;              /* in zephyr/dts/arm/st/f4/stm32f401.dtsi:57 */
			reg = < 0x40003800 0x400 >;         /* in zephyr/dts/arm/st/f4/stm32f401.dtsi:58 */
			clocks = < &rcc 0x40 0x4000 >;      /* in zephyr/dts/arm/st/f4/stm32f401.dtsi:59 */
			interrupts = < 0x24 0x0 >;          /* in zephyr/dts/arm/st/f4/stm32f401.dtsi:60 */
			dmas = < &dma1 0x4 0x0 0x400 0x3 >,
			       < &dma1 0x3 0x0 0x400 0x3 >; /* in zephyr/dts/arm/st/f4/stm32f401.dtsi:61 */
			dma-names = "tx",
			            "rx";                   /* in zephyr/dts/arm/st/f4/stm32f401.dtsi:63 */
			status = "disabled";                /* in zephyr/dts/arm/st/f4/stm32f401.dtsi:64 */
		};

		/* node '/soc/i2s@40003c00' defined in zephyr/dts/arm/st/f4/stm32f401.dtsi:67 */
		i2s3: i2s@40003c00 {
			compatible = "st,stm32-i2s";        /* in zephyr/dts/arm/st/f4/stm32f401.dtsi:68 */
			#address-cells = < 0x1 >;           /* in zephyr/dts/arm/st/f4/stm32f401.dtsi:69 */
			#size-cells = < 0x0 >;              /* in zephyr/dts/arm/st/f4/stm32f401.dtsi:70 */
			reg = < 0x40003c00 0x400 >;         /* in zephyr/dts/arm/st/f4/stm32f401.dtsi:71 */
			clocks = < &rcc 0x40 0x8000 >;      /* in zephyr/dts/arm/st/f4/stm32f401.dtsi:72 */
			interrupts = < 0x33 0x0 >;          /* in zephyr/dts/arm/st/f4/stm32f401.dtsi:73 */
			dmas = < &dma1 0x5 0x0 0x400 0x3 >,
			       < &dma1 0x0 0x0 0x400 0x3 >; /* in zephyr/dts/arm/st/f4/stm32f401.dtsi:74 */
			dma-names = "tx",
			            "rx";                   /* in zephyr/dts/arm/st/f4/stm32f401.dtsi:76 */
			status = "disabled";                /* in zephyr/dts/arm/st/f4/stm32f401.dtsi:77 */
		};

		/* node '/soc/serial@40004800' defined in zephyr/dts/arm/st/f4/stm32f405.dtsi:51 */
		usart3: mikrobus_1_uart: mikrobus_uart: serial@40004800 {
			compatible = "st,stm32-usart",
			             "st,stm32-uart";                  /* in zephyr/dts/arm/st/f4/stm32f405.dtsi:52 */
			reg = < 0x40004800 0x400 >;                    /* in zephyr/dts/arm/st/f4/stm32f405.dtsi:53 */
			clocks = < &rcc 0x40 0x40000 >;                /* in zephyr/dts/arm/st/f4/stm32f405.dtsi:54 */
			resets = < &rctl 0x412 >;                      /* in zephyr/dts/arm/st/f4/stm32f405.dtsi:55 */
			interrupts = < 0x27 0x0 >;                     /* in zephyr/dts/arm/st/f4/stm32f405.dtsi:56 */
			pinctrl-0 = < &usart3_tx_pd8 &usart3_rx_pd9 >; /* in zephyr/boards/mikroe/quail/mikroe_quail.dts:243 */
			pinctrl-names = "default";                     /* in zephyr/boards/mikroe/quail/mikroe_quail.dts:244 */
			current-speed = < 0x1c200 >;                   /* in zephyr/boards/mikroe/quail/mikroe_quail.dts:245 */
			status = "okay";                               /* in zephyr/boards/mikroe/quail/mikroe_quail.dts:246 */
			phandle = < 0x33 >;                            /* in btr-shields/boards/extend/mikroe/quail/mikrobus_sockets.dtsi:52 */
		};

		/* node '/soc/serial@40004c00' defined in zephyr/dts/arm/st/f4/stm32f405.dtsi:60 */
		uart4: serial@40004c00 {
			compatible = "st,stm32-uart";   /* in zephyr/dts/arm/st/f4/stm32f405.dtsi:61 */
			reg = < 0x40004c00 0x400 >;     /* in zephyr/dts/arm/st/f4/stm32f405.dtsi:62 */
			clocks = < &rcc 0x40 0x80000 >; /* in zephyr/dts/arm/st/f4/stm32f405.dtsi:63 */
			resets = < &rctl 0x413 >;       /* in zephyr/dts/arm/st/f4/stm32f405.dtsi:64 */
			interrupts = < 0x34 0x0 >;      /* in zephyr/dts/arm/st/f4/stm32f405.dtsi:65 */
			status = "disabled";            /* in zephyr/dts/arm/st/f4/stm32f405.dtsi:66 */
		};

		/* node '/soc/serial@40005000' defined in zephyr/dts/arm/st/f4/stm32f405.dtsi:69 */
		uart5: serial@40005000 {
			compatible = "st,stm32-uart";    /* in zephyr/dts/arm/st/f4/stm32f405.dtsi:70 */
			reg = < 0x40005000 0x400 >;      /* in zephyr/dts/arm/st/f4/stm32f405.dtsi:71 */
			clocks = < &rcc 0x40 0x100000 >; /* in zephyr/dts/arm/st/f4/stm32f405.dtsi:72 */
			resets = < &rctl 0x414 >;        /* in zephyr/dts/arm/st/f4/stm32f405.dtsi:73 */
			interrupts = < 0x35 0x0 >;       /* in zephyr/dts/arm/st/f4/stm32f405.dtsi:74 */
			status = "disabled";             /* in zephyr/dts/arm/st/f4/stm32f405.dtsi:75 */
		};

		/* node '/soc/timers@40001000' defined in zephyr/dts/arm/st/f4/stm32f405.dtsi:78 */
		timers6: timers@40001000 {
			compatible = "st,stm32-timers"; /* in zephyr/dts/arm/st/f4/stm32f405.dtsi:79 */
			reg = < 0x40001000 0x400 >;     /* in zephyr/dts/arm/st/f4/stm32f405.dtsi:80 */
			clocks = < &rcc 0x40 0x10 >,
			         < &rcc 0x15 0xff >;    /* in zephyr/dts/arm/st/f4/stm32f405.dtsi:81 */
			resets = < &rctl 0x404 >;       /* in zephyr/dts/arm/st/f4/stm32f405.dtsi:83 */
			interrupts = < 0x36 0x0 >;      /* in zephyr/dts/arm/st/f4/stm32f405.dtsi:84 */
			interrupt-names = "global";     /* in zephyr/dts/arm/st/f4/stm32f405.dtsi:85 */
			st,prescaler = < 0x0 >;         /* in zephyr/dts/arm/st/f4/stm32f405.dtsi:86 */
			status = "disabled";            /* in zephyr/dts/arm/st/f4/stm32f405.dtsi:87 */

			/* node '/soc/timers@40001000/counter' defined in zephyr/dts/arm/st/f4/stm32f405.dtsi:89 */
			counter {
				compatible = "st,stm32-counter"; /* in zephyr/dts/arm/st/f4/stm32f405.dtsi:90 */
				status = "disabled";             /* in zephyr/dts/arm/st/f4/stm32f405.dtsi:91 */
			};
		};

		/* node '/soc/timers@40001400' defined in zephyr/dts/arm/st/f4/stm32f405.dtsi:95 */
		timers7: timers@40001400 {
			compatible = "st,stm32-timers"; /* in zephyr/dts/arm/st/f4/stm32f405.dtsi:96 */
			reg = < 0x40001400 0x400 >;     /* in zephyr/dts/arm/st/f4/stm32f405.dtsi:97 */
			clocks = < &rcc 0x40 0x20 >,
			         < &rcc 0x15 0xff >;    /* in zephyr/dts/arm/st/f4/stm32f405.dtsi:98 */
			resets = < &rctl 0x405 >;       /* in zephyr/dts/arm/st/f4/stm32f405.dtsi:100 */
			interrupts = < 0x37 0x0 >;      /* in zephyr/dts/arm/st/f4/stm32f405.dtsi:101 */
			interrupt-names = "global";     /* in zephyr/dts/arm/st/f4/stm32f405.dtsi:102 */
			st,prescaler = < 0x0 >;         /* in zephyr/dts/arm/st/f4/stm32f405.dtsi:103 */
			status = "disabled";            /* in zephyr/dts/arm/st/f4/stm32f405.dtsi:104 */

			/* node '/soc/timers@40001400/counter' defined in zephyr/dts/arm/st/f4/stm32f405.dtsi:106 */
			counter {
				compatible = "st,stm32-counter"; /* in zephyr/dts/arm/st/f4/stm32f405.dtsi:107 */
				status = "disabled";             /* in zephyr/dts/arm/st/f4/stm32f405.dtsi:108 */
			};
		};

		/* node '/soc/timers@40010400' defined in zephyr/dts/arm/st/f4/stm32f405.dtsi:112 */
		timers8: timers@40010400 {
			compatible = "st,stm32-timers"; /* in zephyr/dts/arm/st/f4/stm32f405.dtsi:113 */
			reg = < 0x40010400 0x400 >;     /* in zephyr/dts/arm/st/f4/stm32f405.dtsi:114 */
			clocks = < &rcc 0x44 0x2 >,
			         < &rcc 0x16 0xff >;    /* in zephyr/dts/arm/st/f4/stm32f405.dtsi:115 */
			resets = < &rctl 0x481 >;       /* in zephyr/dts/arm/st/f4/stm32f405.dtsi:117 */
			interrupts = < 0x2b 0x0 >,
			             < 0x2c 0x0 >,
			             < 0x2d 0x0 >,
			             < 0x2e 0x0 >;      /* in zephyr/dts/arm/st/f4/stm32f405.dtsi:118 */
			interrupt-names = "brk",
			                  "up",
			                  "trgcom",
			                  "cc";         /* in zephyr/dts/arm/st/f4/stm32f405.dtsi:119 */
			st,prescaler = < 0x0 >;         /* in zephyr/dts/arm/st/f4/stm32f405.dtsi:120 */
			status = "disabled";            /* in zephyr/dts/arm/st/f4/stm32f405.dtsi:121 */

			/* node '/soc/timers@40010400/pwm' defined in zephyr/dts/arm/st/f4/stm32f405.dtsi:123 */
			pwm {
				compatible = "st,stm32-pwm"; /* in zephyr/dts/arm/st/f4/stm32f405.dtsi:124 */
				status = "disabled";         /* in zephyr/dts/arm/st/f4/stm32f405.dtsi:125 */
				#pwm-cells = < 0x3 >;        /* in zephyr/dts/arm/st/f4/stm32f405.dtsi:126 */
			};

			/* node '/soc/timers@40010400/counter' defined in zephyr/dts/arm/st/f4/stm32f405.dtsi:129 */
			counter {
				compatible = "st,stm32-counter"; /* in zephyr/dts/arm/st/f4/stm32f405.dtsi:130 */
				status = "disabled";             /* in zephyr/dts/arm/st/f4/stm32f405.dtsi:131 */
			};

			/* node '/soc/timers@40010400/qdec' defined in zephyr/dts/arm/st/f4/stm32f405.dtsi:134 */
			qdec {
				compatible = "st,stm32-qdec";    /* in zephyr/dts/arm/st/f4/stm32f405.dtsi:135 */
				st,input-filter-level = < 0x0 >; /* in zephyr/dts/arm/st/f4/stm32f405.dtsi:136 */
				status = "disabled";             /* in zephyr/dts/arm/st/f4/stm32f405.dtsi:137 */
			};
		};

		/* node '/soc/timers@40001800' defined in zephyr/dts/arm/st/f4/stm32f405.dtsi:141 */
		timers12: timers@40001800 {
			compatible = "st,stm32-timers"; /* in zephyr/dts/arm/st/f4/stm32f405.dtsi:142 */
			reg = < 0x40001800 0x400 >;     /* in zephyr/dts/arm/st/f4/stm32f405.dtsi:143 */
			clocks = < &rcc 0x40 0x40 >,
			         < &rcc 0x15 0xff >;    /* in zephyr/dts/arm/st/f4/stm32f405.dtsi:144 */
			resets = < &rctl 0x406 >;       /* in zephyr/dts/arm/st/f4/stm32f405.dtsi:146 */
			interrupts = < 0x2b 0x0 >;      /* in zephyr/dts/arm/st/f4/stm32f405.dtsi:147 */
			interrupt-names = "global";     /* in zephyr/dts/arm/st/f4/stm32f405.dtsi:148 */
			st,prescaler = < 0x0 >;         /* in zephyr/dts/arm/st/f4/stm32f405.dtsi:149 */
			status = "disabled";            /* in zephyr/dts/arm/st/f4/stm32f405.dtsi:150 */

			/* node '/soc/timers@40001800/pwm' defined in zephyr/dts/arm/st/f4/stm32f405.dtsi:152 */
			pwm {
				compatible = "st,stm32-pwm"; /* in zephyr/dts/arm/st/f4/stm32f405.dtsi:153 */
				status = "disabled";         /* in zephyr/dts/arm/st/f4/stm32f405.dtsi:154 */
				#pwm-cells = < 0x3 >;        /* in zephyr/dts/arm/st/f4/stm32f405.dtsi:155 */
			};

			/* node '/soc/timers@40001800/counter' defined in zephyr/dts/arm/st/f4/stm32f405.dtsi:158 */
			counter {
				compatible = "st,stm32-counter"; /* in zephyr/dts/arm/st/f4/stm32f405.dtsi:159 */
				status = "disabled";             /* in zephyr/dts/arm/st/f4/stm32f405.dtsi:160 */
			};
		};

		/* node '/soc/timers@40001c00' defined in zephyr/dts/arm/st/f4/stm32f405.dtsi:164 */
		timers13: timers@40001c00 {
			compatible = "st,stm32-timers"; /* in zephyr/dts/arm/st/f4/stm32f405.dtsi:165 */
			reg = < 0x40001c00 0x400 >;     /* in zephyr/dts/arm/st/f4/stm32f405.dtsi:166 */
			clocks = < &rcc 0x40 0x80 >,
			         < &rcc 0x15 0xff >;    /* in zephyr/dts/arm/st/f4/stm32f405.dtsi:167 */
			resets = < &rctl 0x407 >;       /* in zephyr/dts/arm/st/f4/stm32f405.dtsi:169 */
			interrupts = < 0x2c 0x0 >;      /* in zephyr/dts/arm/st/f4/stm32f405.dtsi:170 */
			interrupt-names = "global";     /* in zephyr/dts/arm/st/f4/stm32f405.dtsi:171 */
			st,prescaler = < 0x0 >;         /* in zephyr/dts/arm/st/f4/stm32f405.dtsi:172 */
			status = "disabled";            /* in zephyr/dts/arm/st/f4/stm32f405.dtsi:173 */

			/* node '/soc/timers@40001c00/pwm' defined in zephyr/dts/arm/st/f4/stm32f405.dtsi:175 */
			pwm {
				compatible = "st,stm32-pwm"; /* in zephyr/dts/arm/st/f4/stm32f405.dtsi:176 */
				status = "disabled";         /* in zephyr/dts/arm/st/f4/stm32f405.dtsi:177 */
				#pwm-cells = < 0x3 >;        /* in zephyr/dts/arm/st/f4/stm32f405.dtsi:178 */
			};

			/* node '/soc/timers@40001c00/counter' defined in zephyr/dts/arm/st/f4/stm32f405.dtsi:181 */
			counter {
				compatible = "st,stm32-counter"; /* in zephyr/dts/arm/st/f4/stm32f405.dtsi:182 */
				status = "disabled";             /* in zephyr/dts/arm/st/f4/stm32f405.dtsi:183 */
			};
		};

		/* node '/soc/timers@40002000' defined in zephyr/dts/arm/st/f4/stm32f405.dtsi:187 */
		timers14: timers@40002000 {
			compatible = "st,stm32-timers"; /* in zephyr/dts/arm/st/f4/stm32f405.dtsi:188 */
			reg = < 0x40002000 0x400 >;     /* in zephyr/dts/arm/st/f4/stm32f405.dtsi:189 */
			clocks = < &rcc 0x40 0x100 >,
			         < &rcc 0x15 0xff >;    /* in zephyr/dts/arm/st/f4/stm32f405.dtsi:190 */
			resets = < &rctl 0x408 >;       /* in zephyr/dts/arm/st/f4/stm32f405.dtsi:192 */
			interrupts = < 0x2d 0x0 >;      /* in zephyr/dts/arm/st/f4/stm32f405.dtsi:193 */
			interrupt-names = "global";     /* in zephyr/dts/arm/st/f4/stm32f405.dtsi:194 */
			st,prescaler = < 0x0 >;         /* in zephyr/dts/arm/st/f4/stm32f405.dtsi:195 */
			status = "disabled";            /* in zephyr/dts/arm/st/f4/stm32f405.dtsi:196 */

			/* node '/soc/timers@40002000/pwm' defined in zephyr/dts/arm/st/f4/stm32f405.dtsi:198 */
			pwm {
				compatible = "st,stm32-pwm"; /* in zephyr/dts/arm/st/f4/stm32f405.dtsi:199 */
				status = "disabled";         /* in zephyr/dts/arm/st/f4/stm32f405.dtsi:200 */
				#pwm-cells = < 0x3 >;        /* in zephyr/dts/arm/st/f4/stm32f405.dtsi:201 */
			};

			/* node '/soc/timers@40002000/counter' defined in zephyr/dts/arm/st/f4/stm32f405.dtsi:204 */
			counter {
				compatible = "st,stm32-counter"; /* in zephyr/dts/arm/st/f4/stm32f405.dtsi:205 */
				status = "disabled";             /* in zephyr/dts/arm/st/f4/stm32f405.dtsi:206 */
			};
		};

		/* node '/soc/usb@40040000' defined in zephyr/dts/arm/st/f4/stm32f405.dtsi:210 */
		usbotg_hs: usb@40040000 {
			compatible = "st,stm32-otghs";     /* in zephyr/dts/arm/st/f4/stm32f405.dtsi:211 */
			reg = < 0x40040000 0x40000 >;      /* in zephyr/dts/arm/st/f4/stm32f405.dtsi:212 */
			interrupts = < 0x4d 0x0 >,
			             < 0x4a 0x0 >,
			             < 0x4b 0x0 >;         /* in zephyr/dts/arm/st/f4/stm32f405.dtsi:213 */
			interrupt-names = "otghs",
			                  "ep1_out",
			                  "ep1_in";        /* in zephyr/dts/arm/st/f4/stm32f405.dtsi:214 */
			num-bidir-endpoints = < 0x6 >;     /* in zephyr/dts/arm/st/f4/stm32f405.dtsi:215 */
			ram-size = < 0x1000 >;             /* in zephyr/dts/arm/st/f4/stm32f405.dtsi:216 */
			maximum-speed = "full-speed";      /* in zephyr/dts/arm/st/f4/stm32f405.dtsi:217 */
			phys = < &otghs_fs_phy >;          /* in zephyr/dts/arm/st/f4/stm32f405.dtsi:218 */
			clocks = < &rcc 0x30 0x20000000 >,
			         < &rcc 0x7 0xff >;        /* in zephyr/dts/arm/st/f4/stm32f405.dtsi:219 */
			status = "disabled";               /* in zephyr/dts/arm/st/f4/stm32f405.dtsi:221 */
		};

		/* node '/soc/can@40006400' defined in zephyr/dts/arm/st/f4/stm32f405.dtsi:224 */
		can1: can@40006400 {
			compatible = "st,stm32-bxcan";    /* in zephyr/dts/arm/st/f4/stm32f405.dtsi:225 */
			reg = < 0x40006400 0x400 >;       /* in zephyr/dts/arm/st/f4/stm32f405.dtsi:226 */
			interrupts = < 0x13 0x0 >,
			             < 0x14 0x0 >,
			             < 0x15 0x0 >,
			             < 0x16 0x0 >;        /* in zephyr/dts/arm/st/f4/stm32f405.dtsi:227 */
			interrupt-names = "TX",
			                  "RX0",
			                  "RX1",
			                  "SCE";          /* in zephyr/dts/arm/st/f4/stm32f405.dtsi:228 */
			clocks = < &rcc 0x40 0x2000000 >; /* in zephyr/dts/arm/st/f4/stm32f405.dtsi:229 */
			status = "disabled";              /* in zephyr/dts/arm/st/f4/stm32f405.dtsi:230 */
		};

		/* node '/soc/can@40006800' defined in zephyr/dts/arm/st/f4/stm32f405.dtsi:233 */
		can2: can@40006800 {
			compatible = "st,stm32-bxcan";    /* in zephyr/dts/arm/st/f4/stm32f405.dtsi:234 */
			reg = < 0x40006800 0x400 >;       /* in zephyr/dts/arm/st/f4/stm32f405.dtsi:235 */
			interrupts = < 0x3f 0x0 >,
			             < 0x40 0x0 >,
			             < 0x41 0x0 >,
			             < 0x42 0x0 >;        /* in zephyr/dts/arm/st/f4/stm32f405.dtsi:236 */
			interrupt-names = "TX",
			                  "RX0",
			                  "RX1",
			                  "SCE";          /* in zephyr/dts/arm/st/f4/stm32f405.dtsi:237 */
			clocks = < &rcc 0x40 0x6000000 >; /* in zephyr/dts/arm/st/f4/stm32f405.dtsi:239 */
			master-can-reg = < 0x40006400 >;  /* in zephyr/dts/arm/st/f4/stm32f405.dtsi:240 */
			status = "disabled";              /* in zephyr/dts/arm/st/f4/stm32f405.dtsi:241 */
		};

		/* node '/soc/rng@50060800' defined in zephyr/dts/arm/st/f4/stm32f405.dtsi:244 */
		rng: rng@50060800 {
			compatible = "st,stm32-rng"; /* in zephyr/dts/arm/st/f4/stm32f405.dtsi:245 */
			reg = < 0x50060800 0x400 >;  /* in zephyr/dts/arm/st/f4/stm32f405.dtsi:246 */
			interrupts = < 0x50 0x0 >;   /* in zephyr/dts/arm/st/f4/stm32f405.dtsi:247 */
			clocks = < &rcc 0x34 0x40 >; /* in zephyr/dts/arm/st/f4/stm32f405.dtsi:248 */
			status = "disabled";         /* in zephyr/dts/arm/st/f4/stm32f405.dtsi:249 */
		};

		/* node '/soc/memory@40024000' defined in zephyr/dts/arm/st/f4/stm32f405.dtsi:252 */
		backup_sram: memory@40024000 {
			compatible = "zephyr,memory-region",
			             "st,stm32-backup-sram";  /* in zephyr/dts/arm/st/f4/stm32f405.dtsi:253 */
			reg = < 0x40024000 0x1000 >;          /* in zephyr/dts/arm/st/f4/stm32f405.dtsi:254 */
			clocks = < &rcc 0x30 0x40000 >;       /* in zephyr/dts/arm/st/f4/stm32f405.dtsi:255 */
			zephyr,memory-region = "BACKUP_SRAM"; /* in zephyr/dts/arm/st/f4/stm32f405.dtsi:256 */
			status = "disabled";                  /* in zephyr/dts/arm/st/f4/stm32f405.dtsi:257 */
		};

		/* node '/soc/adc@40012100' defined in zephyr/dts/arm/st/f4/stm32f405.dtsi:260 */
		adc2: adc@40012100 {
			compatible = "st,stm32f4-adc",
			             "st,stm32-adc";                                 /* in zephyr/dts/arm/st/f4/stm32f405.dtsi:261 */
			reg = < 0x40012100 0x50 >;                                   /* in zephyr/dts/arm/st/f4/stm32f405.dtsi:262 */
			clocks = < &rcc 0x44 0x200 >;                                /* in zephyr/dts/arm/st/f4/stm32f405.dtsi:263 */
			clock-names = "adcx";                                        /* in zephyr/dts/arm/st/f4/stm32f405.dtsi:264 */
			interrupts = < 0x12 0x0 >;                                   /* in zephyr/dts/arm/st/f4/stm32f405.dtsi:265 */
			#io-channel-cells = < 0x1 >;                                 /* in zephyr/dts/arm/st/f4/stm32f405.dtsi:266 */
			st,adc-resolutions = < 0xc 0xa 0x8 0x6 >;                    /* in zephyr/dts/arm/st/f4/stm32f405.dtsi:267 */
			sampling-times = < 0x3 0xf 0x1c 0x38 0x54 0x70 0x90 0x1e0 >; /* in zephyr/dts/arm/st/f4/stm32f405.dtsi:268 */
			st,adc-sequencer = "programmable";                           /* in zephyr/dts/arm/st/f4/stm32f405.dtsi:270 */
			st,adc-oversampler = "none";                                 /* in zephyr/dts/arm/st/f4/stm32f405.dtsi:271 */
			st,adc-internal-regulator = "none";                          /* in zephyr/dts/arm/st/f4/stm32f405.dtsi:272 */
			st,adc-has-injected-support;                                 /* in zephyr/dts/arm/st/f4/stm32f405.dtsi:273 */
			status = "okay";                                             /* in zephyr/boards/mikroe/quail/mikroe_quail.dts:320 */
			pinctrl-0 = < &adc2_in6_pa6 &adc2_in7_pa7 >;                 /* in zephyr/boards/mikroe/quail/mikroe_quail.dts:321 */
			pinctrl-names = "default";                                   /* in zephyr/boards/mikroe/quail/mikroe_quail.dts:322 */
			st,adc-clock-source = "SYNC";                                /* in zephyr/boards/mikroe/quail/mikroe_quail.dts:323 */
			st,adc-prescaler = < 0x2 >;                                  /* in zephyr/boards/mikroe/quail/mikroe_quail.dts:324 */
			phandle = < 0x31 >;                                          /* in zephyr/boards/mikroe/quail/mikroe_quail.dts:43 */
		};

		/* node '/soc/adc@40012200' defined in zephyr/dts/arm/st/f4/stm32f405.dtsi:277 */
		adc3: adc@40012200 {
			compatible = "st,stm32f4-adc",
			             "st,stm32-adc";                                 /* in zephyr/dts/arm/st/f4/stm32f405.dtsi:278 */
			reg = < 0x40012200 0x50 >;                                   /* in zephyr/dts/arm/st/f4/stm32f405.dtsi:279 */
			clocks = < &rcc 0x44 0x400 >;                                /* in zephyr/dts/arm/st/f4/stm32f405.dtsi:280 */
			clock-names = "adcx";                                        /* in zephyr/dts/arm/st/f4/stm32f405.dtsi:281 */
			interrupts = < 0x12 0x0 >;                                   /* in zephyr/dts/arm/st/f4/stm32f405.dtsi:282 */
			#io-channel-cells = < 0x1 >;                                 /* in zephyr/dts/arm/st/f4/stm32f405.dtsi:283 */
			st,adc-resolutions = < 0xc 0xa 0x8 0x6 >;                    /* in zephyr/dts/arm/st/f4/stm32f405.dtsi:284 */
			sampling-times = < 0x3 0xf 0x1c 0x38 0x54 0x70 0x90 0x1e0 >; /* in zephyr/dts/arm/st/f4/stm32f405.dtsi:285 */
			st,adc-clock-source = "SYNC";                                /* in zephyr/dts/arm/st/f4/stm32f405.dtsi:286 */
			st,adc-sequencer = "programmable";                           /* in zephyr/dts/arm/st/f4/stm32f405.dtsi:287 */
			st,adc-oversampler = "none";                                 /* in zephyr/dts/arm/st/f4/stm32f405.dtsi:288 */
			st,adc-internal-regulator = "none";                          /* in zephyr/dts/arm/st/f4/stm32f405.dtsi:289 */
			st,adc-has-injected-support;                                 /* in zephyr/dts/arm/st/f4/stm32f405.dtsi:290 */
			status = "disabled";                                         /* in zephyr/dts/arm/st/f4/stm32f405.dtsi:291 */
		};

		/* node '/soc/dac@40007400' defined in zephyr/dts/arm/st/f4/stm32f405.dtsi:294 */
		dac1: dac@40007400 {
			compatible = "st,stm32-dac";       /* in zephyr/dts/arm/st/f4/stm32f405.dtsi:295 */
			reg = < 0x40007400 0x400 >;        /* in zephyr/dts/arm/st/f4/stm32f405.dtsi:296 */
			clocks = < &rcc 0x40 0x20000000 >; /* in zephyr/dts/arm/st/f4/stm32f405.dtsi:297 */
			status = "disabled";               /* in zephyr/dts/arm/st/f4/stm32f405.dtsi:298 */
			#io-channel-cells = < 0x1 >;       /* in zephyr/dts/arm/st/f4/stm32f405.dtsi:299 */
		};

		/* node '/soc/ethernet@40028000' defined in zephyr/dts/arm/st/f4/stm32f407.dtsi:13 */
		mac: ethernet@40028000 {
			compatible = "st,stm32-ethernet";  /* in zephyr/dts/arm/st/f4/stm32f407.dtsi:14 */
			reg = < 0x40028000 0x8000 >;       /* in zephyr/dts/arm/st/f4/stm32f407.dtsi:15 */
			clock-names = "stm-eth",
			              "mac-clk-tx",
			              "mac-clk-rx",
			              "mac-clk-ptp";       /* in zephyr/dts/arm/st/f4/stm32f407.dtsi:16 */
			clocks = < &rcc 0x30 0x2000000 >,
			         < &rcc 0x30 0x4000000 >,
			         < &rcc 0x30 0x8000000 >,
			         < &rcc 0x30 0x10000000 >; /* in zephyr/dts/arm/st/f4/stm32f407.dtsi:17 */
			interrupts = < 0x3d 0x0 >;         /* in zephyr/dts/arm/st/f4/stm32f407.dtsi:21 */
			status = "disabled";               /* in zephyr/dts/arm/st/f4/stm32f407.dtsi:22 */

			/* node '/soc/ethernet@40028000/mdio' defined in zephyr/dts/arm/st/f4/stm32f407.dtsi:24 */
			mdio: mdio {
				compatible = "st,stm32-mdio",
				             "snps,dwmac-mdio"; /* in zephyr/dts/arm/st/f4/stm32f407.dtsi:25 */
				#address-cells = < 0x1 >;       /* in zephyr/dts/arm/st/f4/stm32f407.dtsi:26 */
				#size-cells = < 0x0 >;          /* in zephyr/dts/arm/st/f4/stm32f407.dtsi:27 */
				status = "disabled";            /* in zephyr/dts/arm/st/f4/stm32f407.dtsi:28 */
			};

			/* node '/soc/ethernet@40028000/ptp-clock' defined in zephyr/dts/arm/st/f4/stm32f407.dtsi:31 */
			ptp_clock: ptp-clock {
				compatible = "snps,dwmac-ptp-clock"; /* in zephyr/dts/arm/st/f4/stm32f407.dtsi:32 */
			};
		};

		/* node '/soc/serial@40007800' defined in zephyr/dts/arm/st/f4/stm32f427.dtsi:48 */
		uart7: serial@40007800 {
			compatible = "st,stm32-uart";      /* in zephyr/dts/arm/st/f4/stm32f427.dtsi:49 */
			reg = < 0x40007800 0x400 >;        /* in zephyr/dts/arm/st/f4/stm32f427.dtsi:50 */
			clocks = < &rcc 0x40 0x40000000 >; /* in zephyr/dts/arm/st/f4/stm32f427.dtsi:51 */
			resets = < &rctl 0x41e >;          /* in zephyr/dts/arm/st/f4/stm32f427.dtsi:52 */
			interrupts = < 0x52 0x0 >;         /* in zephyr/dts/arm/st/f4/stm32f427.dtsi:53 */
			status = "disabled";               /* in zephyr/dts/arm/st/f4/stm32f427.dtsi:54 */
		};

		/* node '/soc/serial@40007c00' defined in zephyr/dts/arm/st/f4/stm32f427.dtsi:57 */
		uart8: serial@40007c00 {
			compatible = "st,stm32-uart";      /* in zephyr/dts/arm/st/f4/stm32f427.dtsi:58 */
			reg = < 0x40007c00 0x400 >;        /* in zephyr/dts/arm/st/f4/stm32f427.dtsi:59 */
			clocks = < &rcc 0x40 0x80000000 >; /* in zephyr/dts/arm/st/f4/stm32f427.dtsi:60 */
			resets = < &rctl 0x41f >;          /* in zephyr/dts/arm/st/f4/stm32f427.dtsi:61 */
			interrupts = < 0x53 0x0 >;         /* in zephyr/dts/arm/st/f4/stm32f427.dtsi:62 */
			status = "disabled";               /* in zephyr/dts/arm/st/f4/stm32f427.dtsi:63 */
		};

		/* node '/soc/memory-controller@a0000000' defined in zephyr/dts/arm/st/f4/stm32f427.dtsi:105 */
		fmc: memory-controller@a0000000 {
			compatible = "st,stm32-fmc"; /* in zephyr/dts/arm/st/f4/stm32f427.dtsi:106 */
			reg = < 0xa0000000 0x400 >;  /* in zephyr/dts/arm/st/f4/stm32f427.dtsi:107 */
			clocks = < &rcc 0x38 0x1 >;  /* in zephyr/dts/arm/st/f4/stm32f427.dtsi:108 */
			status = "disabled";         /* in zephyr/dts/arm/st/f4/stm32f427.dtsi:109 */

			/* node '/soc/memory-controller@a0000000/sdram' defined in zephyr/dts/arm/st/f4/stm32f427.dtsi:111 */
			sdram: sdram {
				compatible = "st,stm32-fmc-sdram"; /* in zephyr/dts/arm/st/f4/stm32f427.dtsi:112 */
				#address-cells = < 0x1 >;          /* in zephyr/dts/arm/st/f4/stm32f427.dtsi:113 */
				#size-cells = < 0x0 >;             /* in zephyr/dts/arm/st/f4/stm32f427.dtsi:114 */
				status = "disabled";               /* in zephyr/dts/arm/st/f4/stm32f427.dtsi:115 */
			};
		};

		/* node '/soc/sai1@40015800' defined in zephyr/dts/arm/st/f4/stm32f427.dtsi:119 */
		sai1: sai1@40015800 {
			compatible = "st,stm32-sai";     /* in zephyr/dts/arm/st/f4/stm32f427.dtsi:120 */
			#address-cells = < 0x1 >;        /* in zephyr/dts/arm/st/f4/stm32f427.dtsi:121 */
			#size-cells = < 0x1 >;           /* in zephyr/dts/arm/st/f4/stm32f427.dtsi:122 */
			reg = < 0x40015800 0x400 >;      /* in zephyr/dts/arm/st/f4/stm32f427.dtsi:123 */
			ranges;                          /* in zephyr/dts/arm/st/f4/stm32f427.dtsi:124 */
			clocks = < &rcc 0x44 0x400000 >; /* in zephyr/dts/arm/st/f4/stm32f427.dtsi:125 */
			status = "disabled";             /* in zephyr/dts/arm/st/f4/stm32f427.dtsi:126 */

			/* node '/soc/sai1@40015800/sai1a@40015804' defined in zephyr/dts/arm/st/f4/stm32f427.dtsi:128 */
			sai1_a: sai1a@40015804 {
				reg = < 0x40015804 0x20 >;            /* in zephyr/dts/arm/st/f4/stm32f427.dtsi:129 */
				dmas = < &dma2 0x1 0x0 0x22800 0x0 >; /* in zephyr/dts/arm/st/f4/stm32f427.dtsi:130 */
				#address-cells = < 0x1 >;             /* in zephyr/dts/arm/st/f4/stm32f427.dtsi:131 */
				#size-cells = < 0x0 >;                /* in zephyr/dts/arm/st/f4/stm32f427.dtsi:132 */
				status = "disabled";                  /* in zephyr/dts/arm/st/f4/stm32f427.dtsi:133 */
			};

			/* node '/soc/sai1@40015800/sai1b@40015824' defined in zephyr/dts/arm/st/f4/stm32f427.dtsi:136 */
			sai1_b: sai1b@40015824 {
				reg = < 0x40015824 0x20 >;            /* in zephyr/dts/arm/st/f4/stm32f427.dtsi:137 */
				dmas = < &dma2 0x5 0x0 0x22800 0x0 >; /* in zephyr/dts/arm/st/f4/stm32f427.dtsi:138 */
				#address-cells = < 0x1 >;             /* in zephyr/dts/arm/st/f4/stm32f427.dtsi:139 */
				#size-cells = < 0x0 >;                /* in zephyr/dts/arm/st/f4/stm32f427.dtsi:140 */
				status = "disabled";                  /* in zephyr/dts/arm/st/f4/stm32f427.dtsi:141 */
			};
		};
	};

	/* node '/cpus' defined in zephyr/dts/arm/st/f4/stm32f4.dtsi:30 */
	cpus {
		#address-cells = < 0x1 >; /* in zephyr/dts/arm/st/f4/stm32f4.dtsi:31 */
		#size-cells = < 0x0 >;    /* in zephyr/dts/arm/st/f4/stm32f4.dtsi:32 */

		/* node '/cpus/cpu@0' defined in zephyr/dts/arm/st/f4/stm32f4.dtsi:34 */
		cpu0: cpu@0 {
			device_type = "cpu";           /* in zephyr/dts/arm/st/f4/stm32f4.dtsi:35 */
			compatible = "arm,cortex-m4f"; /* in zephyr/dts/arm/st/f4/stm32f4.dtsi:36 */
			reg = < 0x0 >;                 /* in zephyr/dts/arm/st/f4/stm32f4.dtsi:37 */
			cpu-power-states = < &stop >;  /* in zephyr/dts/arm/st/f4/stm32f4.dtsi:38 */
		};

		/* node '/cpus/power-states' defined in zephyr/dts/arm/st/f4/stm32f4.dtsi:41 */
		power-states {

			/* node '/cpus/power-states/stop' defined in zephyr/dts/arm/st/f4/stm32f4.dtsi:42 */
			stop: stop {
				compatible = "zephyr,power-state";    /* in zephyr/dts/arm/st/f4/stm32f4.dtsi:43 */
				power-state-name = "suspend-to-idle"; /* in zephyr/dts/arm/st/f4/stm32f4.dtsi:44 */
				min-residency-us = < 0x190 >;         /* in zephyr/dts/arm/st/f4/stm32f4.dtsi:51 */
				exit-latency-us = < 0x12c >;          /* in zephyr/dts/arm/st/f4/stm32f4.dtsi:52 */
				phandle = < 0x26 >;                   /* in zephyr/dts/arm/st/f4/stm32f4.dtsi:38 */
			};
		};
	};

	/* node '/memory@20000000' defined in zephyr/dts/arm/st/f4/stm32f4.dtsi:57 */
	sram0: memory@20000000 {
		compatible = "zephyr,memory-region",
		             "mmio-sram";            /* in zephyr/dts/arm/st/f4/stm32f4.dtsi:58 */
		zephyr,memory-region = "SRAM0";      /* in zephyr/dts/arm/st/f4/stm32f4.dtsi:59 */
		reg = < 0x20000000 0x30000 >;        /* in zephyr/dts/arm/st/f4/stm32f427vi.dtsi:17 */
	};

	/* node '/clocks' defined in zephyr/dts/arm/st/f4/stm32f4.dtsi:62 */
	clocks {

		/* node '/clocks/clk-hse' defined in zephyr/dts/arm/st/f4/stm32f4.dtsi:63 */
		clk_hse: clk-hse {
			#clock-cells = < 0x0 >;            /* in zephyr/dts/arm/st/f4/stm32f4.dtsi:64 */
			compatible = "st,stm32-hse-clock"; /* in zephyr/dts/arm/st/f4/stm32f4.dtsi:65 */
			status = "disabled";               /* in zephyr/dts/arm/st/f4/stm32f4.dtsi:66 */
		};

		/* node '/clocks/clk-hsi' defined in zephyr/dts/arm/st/f4/stm32f4.dtsi:69 */
		clk_hsi: clk-hsi {
			#clock-cells = < 0x0 >;         /* in zephyr/dts/arm/st/f4/stm32f4.dtsi:70 */
			compatible = "fixed-clock";     /* in zephyr/dts/arm/st/f4/stm32f4.dtsi:71 */
			clock-frequency = < 0xf42400 >; /* in zephyr/boards/mikroe/quail/mikroe_quail.dts:207 */
			status = "okay";                /* in zephyr/boards/mikroe/quail/mikroe_quail.dts:208 */
			phandle = < 0x27 >;             /* in zephyr/boards/mikroe/quail/mikroe_quail.dts:216 */
		};

		/* node '/clocks/clk-lse' defined in zephyr/dts/arm/st/f4/stm32f4.dtsi:76 */
		clk_lse: clk-lse {
			#clock-cells = < 0x0 >;       /* in zephyr/dts/arm/st/f4/stm32f4.dtsi:77 */
			compatible = "fixed-clock";   /* in zephyr/dts/arm/st/f4/stm32f4.dtsi:78 */
			clock-frequency = < 0x8000 >; /* in zephyr/dts/arm/st/f4/stm32f4.dtsi:79 */
			status = "disabled";          /* in zephyr/dts/arm/st/f4/stm32f4.dtsi:80 */
		};

		/* node '/clocks/clk-lsi' defined in zephyr/dts/arm/st/f4/stm32f4.dtsi:83 */
		clk_lsi: clk-lsi {
			#clock-cells = < 0x0 >;       /* in zephyr/dts/arm/st/f4/stm32f4.dtsi:84 */
			compatible = "fixed-clock";   /* in zephyr/dts/arm/st/f4/stm32f4.dtsi:85 */
			clock-frequency = < 0x7d00 >; /* in zephyr/dts/arm/st/f4/stm32f4.dtsi:86 */
			status = "okay";              /* in zephyr/boards/mikroe/quail/mikroe_quail.dts:203 */
		};

		/* node '/clocks/pll' defined in zephyr/dts/arm/st/f4/stm32f4.dtsi:90 */
		pll: pll {
			#clock-cells = < 0x0 >;              /* in zephyr/dts/arm/st/f4/stm32f4.dtsi:91 */
			compatible = "st,stm32fx-pll-clock"; /* in zephyr/dts/arm/st/f4/stm32f4.dtsi:92 */
			div-m = < 0x8 >;                     /* in zephyr/boards/mikroe/quail/mikroe_quail.dts:212 */
			mul-n = < 0x60 >;                    /* in zephyr/boards/mikroe/quail/mikroe_quail.dts:213 */
			div-p = < 0x2 >;                     /* in zephyr/boards/mikroe/quail/mikroe_quail.dts:214 */
			div-q = < 0x4 >;                     /* in zephyr/boards/mikroe/quail/mikroe_quail.dts:215 */
			clocks = < &clk_hsi >;               /* in zephyr/boards/mikroe/quail/mikroe_quail.dts:216 */
			status = "okay";                     /* in zephyr/boards/mikroe/quail/mikroe_quail.dts:217 */
			phandle = < 0x2 >;                   /* in zephyr/boards/mikroe/quail/mikroe_quail.dts:221 */
		};

		/* node '/clocks/plli2s' defined in zephyr/dts/arm/st/f4/stm32f401.dtsi:11 */
		plli2s: plli2s {
			#clock-cells = < 0x0 >;              /* in zephyr/dts/arm/st/f4/stm32f401.dtsi:12 */
			compatible = "st,stm32fx-pll-clock"; /* in zephyr/dts/arm/st/f4/stm32f401.dtsi:13 */
			status = "disabled";                 /* in zephyr/dts/arm/st/f4/stm32f401.dtsi:14 */
		};

		/* node '/clocks/pllsai' defined in zephyr/dts/arm/st/f4/stm32f427.dtsi:14 */
		pllsai: pllsai {
			compatible = "st,stm32fx-pll-clock"; /* in zephyr/dts/arm/st/f4/stm32f427.dtsi:15 */
			#clock-cells = < 0x0 >;              /* in zephyr/dts/arm/st/f4/stm32f427.dtsi:16 */
			status = "disabled";                 /* in zephyr/dts/arm/st/f4/stm32f427.dtsi:17 */
		};
	};

	/* node '/mcos' defined in zephyr/dts/arm/st/f4/stm32f4.dtsi:97 */
	mcos {

		/* node '/mcos/mco1' defined in zephyr/dts/arm/st/f4/stm32f4.dtsi:98 */
		mco1: mco1 {
			compatible = "st,stm32-clock-mco"; /* in zephyr/dts/arm/st/f4/stm32f4.dtsi:99 */
			clock-names = "clksel";            /* in zephyr/dts/arm/st/f4/stm32f4.dtsi:100 */
			status = "disabled";               /* in zephyr/dts/arm/st/f4/stm32f4.dtsi:101 */
		};

		/* node '/mcos/mco2' defined in zephyr/dts/arm/st/f4/stm32f4.dtsi:104 */
		mco2: mco2 {
			compatible = "st,stm32-clock-mco"; /* in zephyr/dts/arm/st/f4/stm32f4.dtsi:105 */
			clock-names = "clksel";            /* in zephyr/dts/arm/st/f4/stm32f4.dtsi:106 */
			status = "disabled";               /* in zephyr/dts/arm/st/f4/stm32f4.dtsi:107 */
		};
	};

	/* node '/power@40007000' defined in zephyr/dts/arm/st/f4/stm32f4.dtsi:657 */
	pwr: power@40007000 {
		compatible = "st,stm32-pwr"; /* in zephyr/dts/arm/st/f4/stm32f4.dtsi:658 */
		reg = < 0x40007000 0x400 >;  /* in zephyr/dts/arm/st/f4/stm32f4.dtsi:659 */
		status = "disabled";         /* in zephyr/dts/arm/st/f4/stm32f4.dtsi:660 */
		wkup-pins-nb = < 0x1 >;      /* in zephyr/dts/arm/st/f4/stm32f4.dtsi:662 */
		#address-cells = < 0x1 >;    /* in zephyr/dts/arm/st/f4/stm32f4.dtsi:664 */
		#size-cells = < 0x0 >;       /* in zephyr/dts/arm/st/f4/stm32f4.dtsi:665 */

		/* node '/power@40007000/wkup-pin@1' defined in zephyr/dts/arm/st/f4/stm32f4.dtsi:667 */
		wkup-pin@1 {
			reg = < 0x1 >;                   /* in zephyr/dts/arm/st/f4/stm32f4.dtsi:668 */
			wkup-gpios = < &gpioa 0x0 0x1 >; /* in zephyr/dts/arm/st/f4/stm32f4.dtsi:669 */
		};
	};

	/* node '/dietemp' defined in zephyr/dts/arm/st/f4/stm32f4.dtsi:673 */
	die_temp: dietemp {
		compatible = "st,stm32-temp-cal"; /* in zephyr/dts/arm/st/f4/stm32f4.dtsi:674 */
		nvmem-cells = < &ts_cal1_otp >,
		              < &ts_cal2_otp >;   /* in zephyr/dts/arm/st/f4/stm32f4.dtsi:675 */
		nvmem-cell-names = "TS_CAL1",
		                   "TS_CAL2";     /* in zephyr/dts/arm/st/f4/stm32f4.dtsi:676 */
		ts-cal1-temp = < 0x1e >;          /* in zephyr/dts/arm/st/f4/stm32f4.dtsi:677 */
		ts-cal2-temp = < 0x6e >;          /* in zephyr/dts/arm/st/f4/stm32f4.dtsi:678 */
		ts-cal-vrefanalog = < 0xce4 >;    /* in zephyr/dts/arm/st/f4/stm32f4.dtsi:679 */
		status = "disabled";              /* in zephyr/dts/arm/st/f4/stm32f4.dtsi:681 */
		io-channels = < &adc1 0x12 >;     /* in zephyr/dts/arm/st/f4/stm32f427.dtsi:147 */
	};

	/* node '/vref' defined in zephyr/dts/arm/st/f4/stm32f4.dtsi:684 */
	vref: vref {
		compatible = "st,stm32-vref";   /* in zephyr/dts/arm/st/f4/stm32f4.dtsi:685 */
		nvmem-cells = < &vrefint_otp >; /* in zephyr/dts/arm/st/f4/stm32f4.dtsi:686 */
		vrefint-cal-mv = < 0xce4 >;     /* in zephyr/dts/arm/st/f4/stm32f4.dtsi:687 */
		io-channels = < &adc1 0x11 >;   /* in zephyr/dts/arm/st/f4/stm32f4.dtsi:688 */
		status = "okay";                /* in zephyr/boards/mikroe/quail/mikroe_quail.dts:328 */
	};

	/* node '/vbat' defined in zephyr/dts/arm/st/f4/stm32f4.dtsi:692 */
	vbat: vbat {
		compatible = "st,stm32-vbat"; /* in zephyr/dts/arm/st/f4/stm32f4.dtsi:693 */
		ratio = < 0x4 >;              /* in zephyr/dts/arm/st/f4/stm32f4.dtsi:694 */
		io-channels = < &adc1 0x12 >; /* in zephyr/dts/arm/st/f4/stm32f4.dtsi:695 */
		status = "okay";              /* in zephyr/boards/mikroe/quail/mikroe_quail.dts:332 */
	};

	/* node '/otgfs_phy' defined in zephyr/dts/arm/st/f4/stm32f4.dtsi:699 */
	otgfs_phy: otgfs_phy {
		compatible = "usb-nop-xceiv"; /* in zephyr/dts/arm/st/f4/stm32f4.dtsi:700 */
		#phy-cells = < 0x0 >;         /* in zephyr/dts/arm/st/f4/stm32f4.dtsi:701 */
		phandle = < 0x15 >;           /* in zephyr/dts/arm/st/f4/stm32f4.dtsi:373 */
	};

	/* node '/smbus1' defined in zephyr/dts/arm/st/f4/stm32f4.dtsi:704 */
	smbus1: smbus1 {
		compatible = "st,stm32-smbus"; /* in zephyr/dts/arm/st/f4/stm32f4.dtsi:705 */
		#address-cells = < 0x1 >;      /* in zephyr/dts/arm/st/f4/stm32f4.dtsi:706 */
		#size-cells = < 0x0 >;         /* in zephyr/dts/arm/st/f4/stm32f4.dtsi:707 */
		i2c = < &i2c1 >;               /* in zephyr/dts/arm/st/f4/stm32f4.dtsi:708 */
		status = "disabled";           /* in zephyr/dts/arm/st/f4/stm32f4.dtsi:709 */
	};

	/* node '/smbus2' defined in zephyr/dts/arm/st/f4/stm32f4.dtsi:712 */
	smbus2: smbus2 {
		compatible = "st,stm32-smbus"; /* in zephyr/dts/arm/st/f4/stm32f4.dtsi:713 */
		#address-cells = < 0x1 >;      /* in zephyr/dts/arm/st/f4/stm32f4.dtsi:714 */
		#size-cells = < 0x0 >;         /* in zephyr/dts/arm/st/f4/stm32f4.dtsi:715 */
		i2c = < &i2c2 >;               /* in zephyr/dts/arm/st/f4/stm32f4.dtsi:716 */
		status = "disabled";           /* in zephyr/dts/arm/st/f4/stm32f4.dtsi:717 */
	};

	/* node '/smbus3' defined in zephyr/dts/arm/st/f4/stm32f4.dtsi:720 */
	smbus3: smbus3 {
		compatible = "st,stm32-smbus"; /* in zephyr/dts/arm/st/f4/stm32f4.dtsi:721 */
		#address-cells = < 0x1 >;      /* in zephyr/dts/arm/st/f4/stm32f4.dtsi:722 */
		#size-cells = < 0x0 >;         /* in zephyr/dts/arm/st/f4/stm32f4.dtsi:723 */
		i2c = < &i2c3 >;               /* in zephyr/dts/arm/st/f4/stm32f4.dtsi:724 */
		status = "disabled";           /* in zephyr/dts/arm/st/f4/stm32f4.dtsi:725 */
	};

	/* node '/otghs_fs_phy' defined in zephyr/dts/arm/st/f4/stm32f405.dtsi:303 */
	otghs_fs_phy: otghs_fs_phy {
		compatible = "usb-nop-xceiv"; /* in zephyr/dts/arm/st/f4/stm32f405.dtsi:304 */
		#phy-cells = < 0x0 >;         /* in zephyr/dts/arm/st/f4/stm32f405.dtsi:305 */
		phandle = < 0x22 >;           /* in zephyr/dts/arm/st/f4/stm32f405.dtsi:218 */
	};

	/* node '/memory@10000000' defined in zephyr/dts/arm/st/f4/stm32f427vi.dtsi:10 */
	ccm0: memory@10000000 {
		compatible = "zephyr,memory-region",
		             "st,stm32-ccm";         /* in zephyr/dts/arm/st/f4/stm32f427vi.dtsi:11 */
		reg = < 0x10000000 0x10000 >;        /* in zephyr/dts/arm/st/f4/stm32f427vi.dtsi:12 */
		zephyr,memory-region = "DTCM";       /* in zephyr/dts/arm/st/f4/stm32f427vi.dtsi:13 */
	};

	/* node '/leds' defined in zephyr/boards/mikroe/quail/mikroe_quail.dts:23 */
	leds {
		compatible = "gpio-leds"; /* in zephyr/boards/mikroe/quail/mikroe_quail.dts:24 */

		/* node '/leds/led_1' defined in zephyr/boards/mikroe/quail/mikroe_quail.dts:26 */
		ld1: led_1 {
			gpios = < &gpioe 0xf 0x0 >; /* in zephyr/boards/mikroe/quail/mikroe_quail.dts:27 */
			label = "User LD1";         /* in zephyr/boards/mikroe/quail/mikroe_quail.dts:28 */
		};

		/* node '/leds/led_2' defined in zephyr/boards/mikroe/quail/mikroe_quail.dts:31 */
		ld2: led_2 {
			gpios = < &gpioe 0xa 0x0 >; /* in zephyr/boards/mikroe/quail/mikroe_quail.dts:32 */
			label = "User LD2";         /* in zephyr/boards/mikroe/quail/mikroe_quail.dts:33 */
		};

		/* node '/leds/led_3' defined in zephyr/boards/mikroe/quail/mikroe_quail.dts:36 */
		ld3: led_3 {
			gpios = < &gpioc 0x3 0x0 >; /* in zephyr/boards/mikroe/quail/mikroe_quail.dts:37 */
			label = "User LD3";         /* in zephyr/boards/mikroe/quail/mikroe_quail.dts:38 */
		};
	};

	/* node '/zephyr,user' defined in zephyr/boards/mikroe/quail/mikroe_quail.dts:42 */
	zephyr,user {
		io-channels = < &adc1 0x0 >,
		              < &adc1 0x1 >,
		              < &adc2 0x0 >,
		              < &adc2 0x1 >; /* in zephyr/boards/mikroe/quail/mikroe_quail.dts:43 */
	};

	/* node '/mikrobus-connector-1' defined in zephyr/boards/mikroe/quail/mikroe_quail.dts:46 */
	mikrobus_1_header: mikrobus_header: mikrobus-connector-1 {
		compatible = "mikro-bus";                  /* in zephyr/boards/mikroe/quail/mikroe_quail.dts:47 */
		#gpio-cells = < 0x2 >;                     /* in zephyr/boards/mikroe/quail/mikroe_quail.dts:48 */
		gpio-map-mask = < 0xffffffff 0xffffffc0 >; /* in zephyr/boards/mikroe/quail/mikroe_quail.dts:49 */
		gpio-map-pass-thru = < 0x0 0x3f >;         /* in zephyr/boards/mikroe/quail/mikroe_quail.dts:50 */
		gpio-map = < 0x0 0x0 &gpioa 0x6 0x0 >,
		           < 0x1 0x0 &gpioa 0x2 0x0 >,
		           < 0x2 0x0 &gpioa 0x3 0x0 >,
		           < 0x3 0x0 &gpiob 0x3 0x0 >,
		           < 0x4 0x0 &gpiob 0x4 0x0 >,
		           < 0x5 0x0 &gpiob 0x5 0x0 >,
		           < 0x6 0x0 &gpioe 0x9 0x0 >,
		           < 0x7 0x0 &gpioa 0x1 0x0 >,
		           < 0x8 0x0 &gpiod 0x9 0x0 >,
		           < 0x9 0x0 &gpiod 0x8 0x0 >,
		           < 0xa 0x0 &gpiob 0x6 0x0 >,
		           < 0xb 0x0 &gpiob 0x7 0x0 >;     /* in zephyr/boards/mikroe/quail/mikroe_quail.dts:51 */
	};

	/* node '/mikrobus-connector-2' defined in zephyr/boards/mikroe/quail/mikroe_quail.dts:69 */
	mikrobus_2_header: mikrobus-connector-2 {
		compatible = "mikro-bus";                  /* in zephyr/boards/mikroe/quail/mikroe_quail.dts:70 */
		#gpio-cells = < 0x2 >;                     /* in zephyr/boards/mikroe/quail/mikroe_quail.dts:71 */
		gpio-map-mask = < 0xffffffff 0xffffffc0 >; /* in zephyr/boards/mikroe/quail/mikroe_quail.dts:72 */
		gpio-map-pass-thru = < 0x0 0x3f >;         /* in zephyr/boards/mikroe/quail/mikroe_quail.dts:73 */
		gpio-map = < 0x0 0x0 &gpioa 0x4 0x0 >,
		           < 0x1 0x0 &gpioe 0x1 0x0 >,
		           < 0x2 0x0 &gpioe 0x0 0x0 >,
		           < 0x3 0x0 &gpiob 0x3 0x0 >,
		           < 0x4 0x0 &gpiob 0x4 0x0 >,
		           < 0x5 0x0 &gpiob 0x5 0x0 >,
		           < 0x6 0x0 &gpiod 0xf 0x0 >,
		           < 0x7 0x0 &gpiob 0x9 0x0 >,
		           < 0x8 0x0 &gpiod 0x6 0x0 >,
		           < 0x9 0x0 &gpiod 0x5 0x0 >,
		           < 0xa 0x0 &gpiob 0x6 0x0 >,
		           < 0xb 0x0 &gpiob 0x7 0x0 >;     /* in zephyr/boards/mikroe/quail/mikroe_quail.dts:74 */
	};

	/* node '/mikrobus-connector-3' defined in zephyr/boards/mikroe/quail/mikroe_quail.dts:92 */
	mikrobus_3_header: mikrobus-connector-3 {
		compatible = "mikro-bus";                  /* in zephyr/boards/mikroe/quail/mikroe_quail.dts:93 */
		#gpio-cells = < 0x2 >;                     /* in zephyr/boards/mikroe/quail/mikroe_quail.dts:94 */
		gpio-map-mask = < 0xffffffff 0xffffffc0 >; /* in zephyr/boards/mikroe/quail/mikroe_quail.dts:95 */
		gpio-map-pass-thru = < 0x0 0x3f >;         /* in zephyr/boards/mikroe/quail/mikroe_quail.dts:96 */
		gpio-map = < 0x0 0x0 &gpioa 0x7 0x0 >,
		           < 0x1 0x0 &gpiod 0x8 0x0 >,
		           < 0x2 0x0 &gpiod 0xb 0x0 >,
		           < 0x3 0x0 &gpioc 0xa 0x0 >,
		           < 0x4 0x0 &gpioc 0xb 0x0 >,
		           < 0x5 0x0 &gpioc 0xc 0x0 >,
		           < 0x6 0x0 &gpiod 0xd 0x0 >,
		           < 0x7 0x0 &gpioc 0x8 0x0 >,
		           < 0x8 0x0 &gpioc 0x7 0x0 >,
		           < 0x9 0x0 &gpioc 0x6 0x0 >,
		           < 0xa 0x0 &gpiob 0x6 0x0 >,
		           < 0xb 0x0 &gpiob 0x7 0x0 >;     /* in zephyr/boards/mikroe/quail/mikroe_quail.dts:97 */
	};

	/* node '/mikrobus-connector-4' defined in zephyr/boards/mikroe/quail/mikroe_quail.dts:115 */
	mikrobus_4_header: mikrobus-connector-4 {
		compatible = "mikro-bus";                  /* in zephyr/boards/mikroe/quail/mikroe_quail.dts:116 */
		#gpio-cells = < 0x2 >;                     /* in zephyr/boards/mikroe/quail/mikroe_quail.dts:117 */
		gpio-map-mask = < 0xffffffff 0xffffffc0 >; /* in zephyr/boards/mikroe/quail/mikroe_quail.dts:118 */
		gpio-map-pass-thru = < 0x0 0x3f >;         /* in zephyr/boards/mikroe/quail/mikroe_quail.dts:119 */
		gpio-map = < 0x0 0x0 &gpioa 0x5 0x0 >,
		           < 0x1 0x0 &gpiod 0x0 0x0 >,
		           < 0x2 0x0 &gpiod 0x1 0x0 >,
		           < 0x3 0x0 &gpioc 0xa 0x0 >,
		           < 0x4 0x0 &gpioc 0xb 0x0 >,
		           < 0x5 0x0 &gpioc 0xc 0x0 >,
		           < 0x6 0x0 &gpiod 0xe 0x0 >,
		           < 0x7 0x0 &gpioa 0xe 0x0 >,
		           < 0x8 0x0 &gpioa 0xa 0x0 >,
		           < 0x9 0x0 &gpioa 0x9 0x0 >,
		           < 0xa 0x0 &gpiob 0x6 0x0 >,
		           < 0xb 0x0 &gpiob 0x7 0x0 >;     /* in zephyr/boards/mikroe/quail/mikroe_quail.dts:120 */
	};

	/* node '/connector' defined in zephyr/boards/mikroe/quail/mikroe_quail.dts:138 */
	edge_header: connector {
		#gpio-cells = < 0x2 >;                     /* in zephyr/boards/mikroe/quail/mikroe_quail.dts:139 */
		gpio-map-mask = < 0xffffffff 0xffffffc0 >; /* in zephyr/boards/mikroe/quail/mikroe_quail.dts:140 */
		gpio-map-pass-thru = < 0x0 0x3f >;         /* in zephyr/boards/mikroe/quail/mikroe_quail.dts:141 */
		gpio-map = < 0x0 0x0 &gpioc 0x5 0x0 >,
		           < 0x1 0x0 &gpiob 0x0 0x0 >,
		           < 0x2 0x0 &gpioe 0x7 0x0 >,
		           < 0x3 0x0 &gpioe 0x8 0x0 >,
		           < 0x4 0x0 &gpioe 0xb 0x0 >,
		           < 0x5 0x0 &gpioc 0x4 0x0 >,
		           < 0x6 0x0 &gpioe 0xd 0x0 >,
		           < 0x7 0x0 &gpioe 0xe 0x0 >,
		           < 0x8 0x0 &gpiob 0xa 0x0 >,
		           < 0x9 0x0 &gpiob 0xb 0x0 >,
		           < 0xa 0x0 &gpiob 0xc 0x0 >,
		           < 0xb 0x0 &gpiob 0xd 0x0 >,
		           < 0xc 0x0 &gpiob 0x6 0x0 >,
		           < 0xd 0x0 &gpiob 0x7 0x0 >,
		           < 0xe 0x0 &gpioc 0xa 0x0 >,
		           < 0xf 0x0 &gpioc 0xb 0x0 >,
		           < 0x10 0x0 &gpioc 0xc 0x0 >,
		           < 0x11 0x0 &gpiod 0xa 0x0 >,
		           < 0x12 0x0 &gpioa 0xf 0x0 >,
		           < 0x13 0x0 &gpioc 0xd 0x0 >,
		           < 0x14 0x0 &gpioe 0x6 0x0 >,
		           < 0x15 0x0 &gpioe 0x5 0x0 >,
		           < 0x16 0x0 &gpiod 0x2 0x0 >,
		           < 0x17 0x0 &gpiod 0x3 0x0 >,
		           < 0x18 0x0 &gpiod 0x4 0x0 >,
		           < 0x19 0x0 &gpiod 0x7 0x0 >,
		           < 0x1a 0x0 &gpioe 0x2 0x0 >,
		           < 0x1b 0x0 &gpioe 0x3 0x0 >,
		           < 0x1c 0x0 &gpioe 0x4 0x0 >;    /* in zephyr/boards/mikroe/quail/mikroe_quail.dts:142 */
	};

	/* node '/socket_1_adc' defined in zephyr/boards/mikroe/quail/mikroe_quail.dts:181 */
	skd1: mikrobus_1_adc: mikrobus_adc: socket_1_adc {
		status = "okay";             /* in zephyr/boards/mikroe/quail/mikroe_quail.dts:182 */
		io-channels = < &adc2 0x0 >; /* in zephyr/boards/mikroe/quail/mikroe_quail.dts:183 */
	};

	/* node '/socket_2_adc' defined in zephyr/boards/mikroe/quail/mikroe_quail.dts:186 */
	skd2: mikrobus_2_adc: socket_2_adc {
		status = "okay";             /* in zephyr/boards/mikroe/quail/mikroe_quail.dts:187 */
		io-channels = < &adc1 0x0 >; /* in zephyr/boards/mikroe/quail/mikroe_quail.dts:188 */
	};

	/* node '/socket_3_adc' defined in zephyr/boards/mikroe/quail/mikroe_quail.dts:191 */
	skd3: mikrobus_3_adc: socket_3_adc {
		status = "okay";             /* in zephyr/boards/mikroe/quail/mikroe_quail.dts:192 */
		io-channels = < &adc2 0x1 >; /* in zephyr/boards/mikroe/quail/mikroe_quail.dts:193 */
	};

	/* node '/socket_4_adc' defined in zephyr/boards/mikroe/quail/mikroe_quail.dts:196 */
	skd4: mikrobus_4_adc: socket_4_adc {
		status = "okay";             /* in zephyr/boards/mikroe/quail/mikroe_quail.dts:197 */
		io-channels = < &adc1 0x1 >; /* in zephyr/boards/mikroe/quail/mikroe_quail.dts:198 */
	};

	/* node '/connector_mikrobus_1' defined in btr-shields/boards/extend/mikroe/quail/mikrobus_sockets.dtsi:33 */
	quail_sock1: mikrobus_1: connector_mikrobus_1 {
		compatible = "socket,mikrobus";            /* in btr-shields/boards/extend/mikroe/quail/mikrobus_sockets.dtsi:34 */
		#gpio-cells = < 0x2 >;                     /* in btr-shields/boards/extend/mikroe/quail/mikrobus_sockets.dtsi:35 */
		gpio-map-mask = < 0xffffffff 0xffffffc0 >; /* in btr-shields/boards/extend/mikroe/quail/mikrobus_sockets.dtsi:36 */
		gpio-map-pass-thru = < 0x0 0x3f >;         /* in btr-shields/boards/extend/mikroe/quail/mikrobus_sockets.dtsi:37 */
		gpio-map = < 0x0 0x0 &gpioa 0x6 0x0 >,
		           < 0x1 0x0 &gpioa 0x2 0x0 >,
		           < 0x2 0x0 &gpioa 0x3 0x0 >,
		           < 0x3 0x0 &gpiob 0x3 0x0 >,
		           < 0x4 0x0 &gpiob 0x4 0x0 >,
		           < 0x5 0x0 &gpiob 0x5 0x0 >,
		           < 0x6 0x0 &gpioe 0x9 0x0 >,
		           < 0x7 0x0 &gpioa 0x1 0x0 >,
		           < 0x8 0x0 &gpiod 0x9 0x0 >,
		           < 0x9 0x0 &gpiod 0x8 0x0 >,
		           < 0xa 0x0 &gpiob 0x6 0x0 >,
		           < 0xb 0x0 &gpiob 0x7 0x0 >;     /* in btr-shields/boards/extend/mikroe/quail/mikrobus_sockets.dtsi:38 */
		socket,spi = < &spi1 >;                    /* in btr-shields/boards/extend/mikroe/quail/mikrobus_sockets.dtsi:50 */
		socket,i2c = < &i2c1 >;                    /* in btr-shields/boards/extend/mikroe/quail/mikrobus_sockets.dtsi:51 */
		socket,uart = < &usart3 >;                 /* in btr-shields/boards/extend/mikroe/quail/mikrobus_sockets.dtsi:52 */
		phandle = < 0x13 >;                        /* in <RIGC_BUILD>/rig/rig-gen.overlay:21 */
	};

	/* node '/connector_mikrobus_2' defined in btr-shields/boards/extend/mikroe/quail/mikrobus_sockets.dtsi:55 */
	quail_sock2: mikrobus_2: connector_mikrobus_2 {
		compatible = "socket,mikrobus";            /* in btr-shields/boards/extend/mikroe/quail/mikrobus_sockets.dtsi:56 */
		#gpio-cells = < 0x2 >;                     /* in btr-shields/boards/extend/mikroe/quail/mikrobus_sockets.dtsi:57 */
		gpio-map-mask = < 0xffffffff 0xffffffc0 >; /* in btr-shields/boards/extend/mikroe/quail/mikrobus_sockets.dtsi:58 */
		gpio-map-pass-thru = < 0x0 0x3f >;         /* in btr-shields/boards/extend/mikroe/quail/mikrobus_sockets.dtsi:59 */
		gpio-map = < 0x0 0x0 &gpioa 0x4 0x0 >,
		           < 0x1 0x0 &gpioe 0x1 0x0 >,
		           < 0x2 0x0 &gpioe 0x0 0x0 >,
		           < 0x3 0x0 &gpiob 0x3 0x0 >,
		           < 0x4 0x0 &gpiob 0x4 0x0 >,
		           < 0x5 0x0 &gpiob 0x5 0x0 >,
		           < 0x6 0x0 &gpiod 0xf 0x0 >,
		           < 0x7 0x0 &gpiob 0x9 0x0 >,
		           < 0x8 0x0 &gpiod 0x6 0x0 >,
		           < 0x9 0x0 &gpiod 0x5 0x0 >,
		           < 0xa 0x0 &gpiob 0x6 0x0 >,
		           < 0xb 0x0 &gpiob 0x7 0x0 >;     /* in btr-shields/boards/extend/mikroe/quail/mikrobus_sockets.dtsi:60 */
		socket,spi = < &spi1 >;                    /* in btr-shields/boards/extend/mikroe/quail/mikrobus_sockets.dtsi:72 */
		socket,i2c = < &i2c1 >;                    /* in btr-shields/boards/extend/mikroe/quail/mikrobus_sockets.dtsi:73 */
		socket,uart = < &usart2 >;                 /* in btr-shields/boards/extend/mikroe/quail/mikrobus_sockets.dtsi:74 */
		phandle = < 0x14 >;                        /* in <RIGC_BUILD>/rig/rig-gen.overlay:21 */
	};

	/* node '/connector_mikrobus_3' defined in btr-shields/boards/extend/mikroe/quail/mikrobus_sockets.dtsi:77 */
	quail_sock3: mikrobus_3: connector_mikrobus_3 {
		compatible = "socket,mikrobus";            /* in btr-shields/boards/extend/mikroe/quail/mikrobus_sockets.dtsi:78 */
		#gpio-cells = < 0x2 >;                     /* in btr-shields/boards/extend/mikroe/quail/mikrobus_sockets.dtsi:79 */
		gpio-map-mask = < 0xffffffff 0xffffffc0 >; /* in btr-shields/boards/extend/mikroe/quail/mikrobus_sockets.dtsi:80 */
		gpio-map-pass-thru = < 0x0 0x3f >;         /* in btr-shields/boards/extend/mikroe/quail/mikrobus_sockets.dtsi:81 */
		gpio-map = < 0x0 0x0 &gpioa 0x7 0x0 >,
		           < 0x1 0x0 &gpiod 0x8 0x0 >,
		           < 0x2 0x0 &gpiod 0xb 0x0 >,
		           < 0x3 0x0 &gpioc 0xa 0x0 >,
		           < 0x4 0x0 &gpioc 0xb 0x0 >,
		           < 0x5 0x0 &gpioc 0xc 0x0 >,
		           < 0x6 0x0 &gpiod 0xd 0x0 >,
		           < 0x7 0x0 &gpioc 0x8 0x0 >,
		           < 0x8 0x0 &gpioc 0x7 0x0 >,
		           < 0x9 0x0 &gpioc 0x6 0x0 >,
		           < 0xa 0x0 &gpiob 0x6 0x0 >,
		           < 0xb 0x0 &gpiob 0x7 0x0 >;     /* in btr-shields/boards/extend/mikroe/quail/mikrobus_sockets.dtsi:82 */
		socket,spi = < &spi3 >;                    /* in btr-shields/boards/extend/mikroe/quail/mikrobus_sockets.dtsi:94 */
		socket,i2c = < &i2c1 >;                    /* in btr-shields/boards/extend/mikroe/quail/mikrobus_sockets.dtsi:95 */
		socket,uart = < &usart6 >;                 /* in btr-shields/boards/extend/mikroe/quail/mikrobus_sockets.dtsi:96 */
		phandle = < 0xe >;                         /* in <RIGC_BUILD>/rig/rig-gen.overlay:9 */
	};

	/* node '/connector_mikrobus_4' defined in btr-shields/boards/extend/mikroe/quail/mikrobus_sockets.dtsi:99 */
	quail_sock4: mikrobus_4: connector_mikrobus_4 {
		compatible = "socket,mikrobus";            /* in btr-shields/boards/extend/mikroe/quail/mikrobus_sockets.dtsi:100 */
		#gpio-cells = < 0x2 >;                     /* in btr-shields/boards/extend/mikroe/quail/mikrobus_sockets.dtsi:101 */
		gpio-map-mask = < 0xffffffff 0xffffffc0 >; /* in btr-shields/boards/extend/mikroe/quail/mikrobus_sockets.dtsi:102 */
		gpio-map-pass-thru = < 0x0 0x3f >;         /* in btr-shields/boards/extend/mikroe/quail/mikrobus_sockets.dtsi:103 */
		gpio-map = < 0x0 0x0 &gpioa 0x5 0x0 >,
		           < 0x1 0x0 &gpiod 0x0 0x0 >,
		           < 0x2 0x0 &gpiod 0x1 0x0 >,
		           < 0x3 0x0 &gpioc 0xa 0x0 >,
		           < 0x4 0x0 &gpioc 0xb 0x0 >,
		           < 0x5 0x0 &gpioc 0xc 0x0 >,
		           < 0x6 0x0 &gpiod 0xe 0x0 >,
		           < 0x7 0x0 &gpioa 0xe 0x0 >,
		           < 0x8 0x0 &gpioa 0xa 0x0 >,
		           < 0x9 0x0 &gpioa 0x9 0x0 >,
		           < 0xa 0x0 &gpiob 0x6 0x0 >,
		           < 0xb 0x0 &gpiob 0x7 0x0 >;     /* in btr-shields/boards/extend/mikroe/quail/mikrobus_sockets.dtsi:104 */
		socket,spi = < &spi3 >;                    /* in btr-shields/boards/extend/mikroe/quail/mikrobus_sockets.dtsi:116 */
		socket,i2c = < &i2c1 >;                    /* in btr-shields/boards/extend/mikroe/quail/mikrobus_sockets.dtsi:117 */
		socket,uart = < &usart1 >;                 /* in btr-shields/boards/extend/mikroe/quail/mikrobus_sockets.dtsi:118 */
		phandle = < 0xf >;                         /* in <RIGC_BUILD>/rig/rig-gen.overlay:15 */
	};
};
